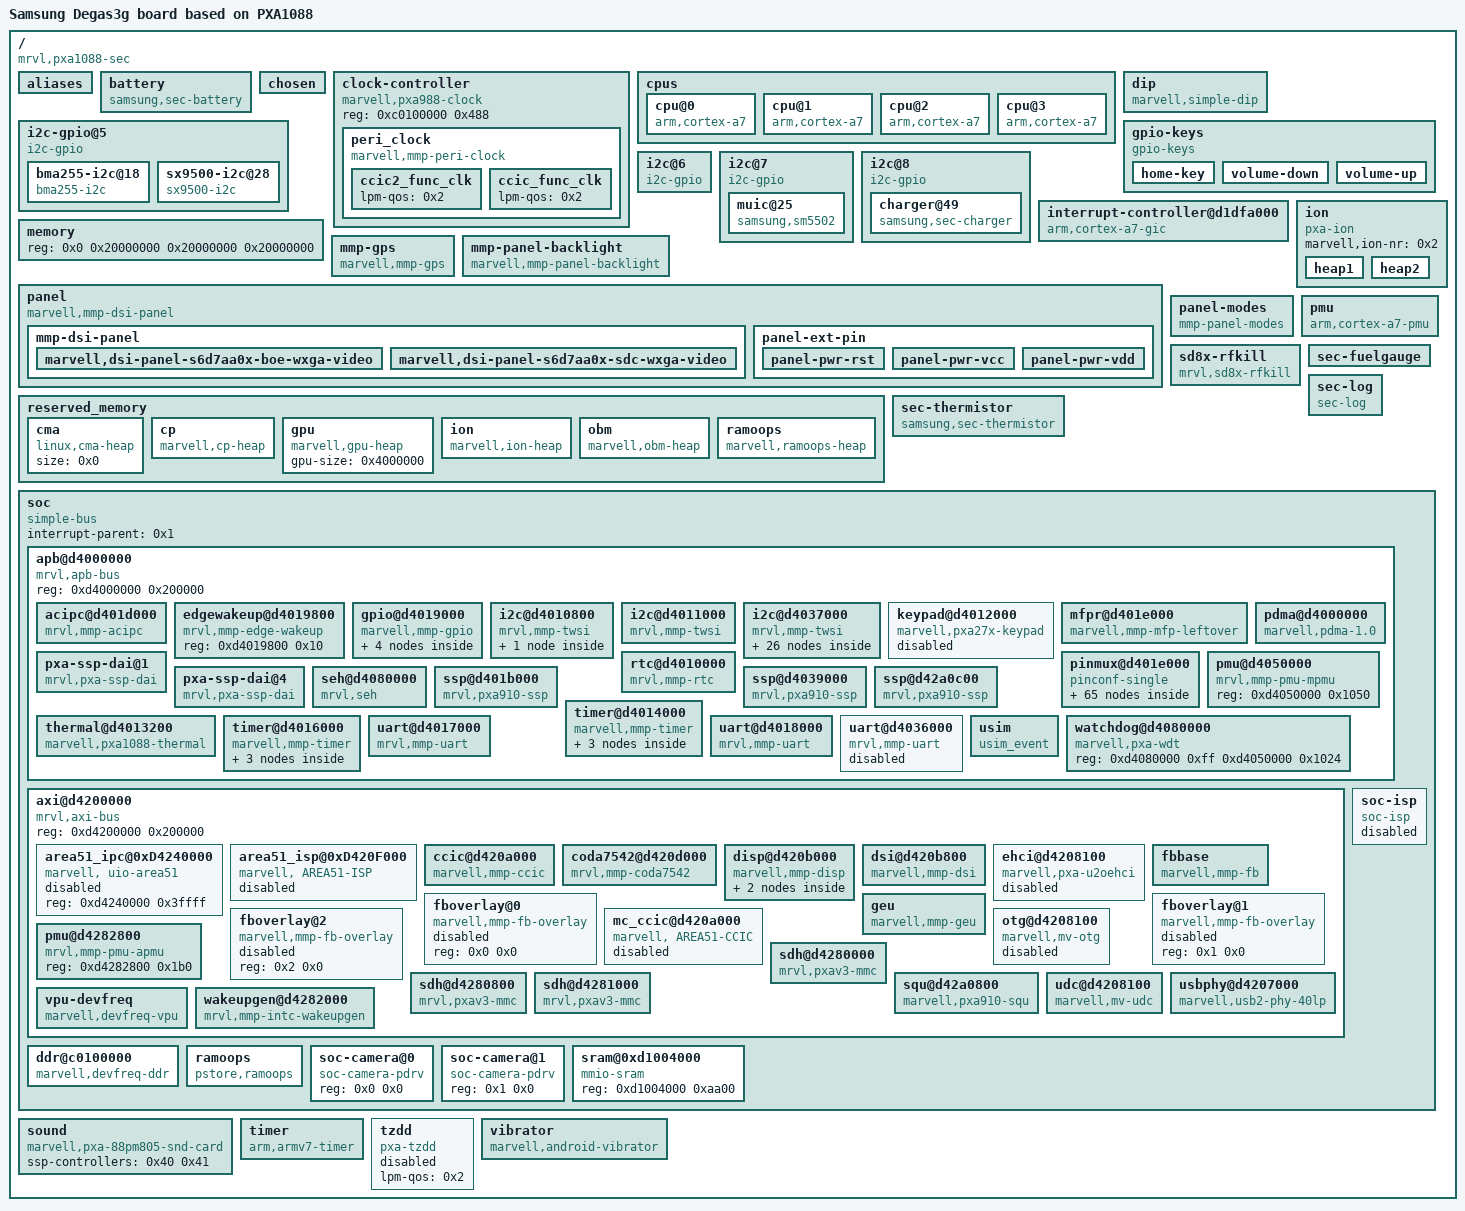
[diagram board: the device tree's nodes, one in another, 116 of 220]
/dts-v1/;

/ {
	#address-cells = <0x1>;
	#size-cells = <0x1>;
	compatible = "mrvl,pxa1088-sec", "mrvl,pxa1088";
	interrupt-parent = <0x1>;
	model = "Samsung Degas3g board based on PXA1088";
	pxa,rev-id = <0xf45 0x1>;

	aliases {
		area51-ccic0 = "/soc/axi@d4200000/mc_ccic@d420a000";
		i2c0 = "/soc/apb@d4000000/i2c@d4011000";
		i2c1 = "/soc/apb@d4000000/i2c@d4010800";
		i2c2 = "/soc/apb@d4000000/i2c@d4037000";
		i2c5 = "/i2c-gpio@5";
		i2c6 = "/i2c@6";
		i2c7 = "/i2c@7";
		i2c8 = "/i2c@8";
		mmp-camera0 = "/soc/axi@d4200000/ccic@d420a000";
		serial0 = "/soc/apb@d4000000/uart@d4036000";
		serial1 = "/soc/apb@d4000000/uart@d4017000";
		serial2 = "/soc/apb@d4000000/uart@d4018000";
	};

	battery {
		adc_check_count = <0x5>;
		battery_check_type = <0x4>;
		cable_check_type = <0x5>;
		cable_source_type = <0x1>;
		charger_name = "sec-charger";
		charging_reset_time = <0x0>;
		charging_total_time = <0x5460>;
		check_adc_max = <0x5a0>;
		check_adc_min = <0x0>;
		check_count = <0x0>;
		chg_gpio_full_check = <0x0>;
		chg_polarity_full_check = <0x1>;
		chip_vendor = "LSI";
		compatible = "samsung,sec-battery";
		event_waiting_time = <0x258>;
		fast_charging_current = <0x3e8 0x0 0x0 0x4b0 0x1cc 0x3e8 0x3e8 0x1cc 0x1f4 0x0 0x384 0x3e8 0x0 0x0 0x0 0x190 0x2bc 0x3e8 0x12c 0x3e8 0x3e8>;
		fuelgauge_name = "sec-fuelgauge";
		full_check_count = <0x1>;
		full_check_current_1st = <0xfa 0x0 0x0 0xfa 0xfa 0xfa 0xfa 0xfa 0xfa 0x0 0xfa 0xfa 0x0 0x0 0x0 0xfa 0xfa 0xfa 0xfa 0xfa 0xfa>;
		full_check_current_2nd = <0x960 0x0 0x0 0x960 0x960 0x960 0x960 0x960 0x960 0x0 0x960 0x960 0x0 0x0 0x0 0x960 0x960 0x960 0x960 0x960 0x960>;
		full_check_type = <0x7>;
		full_check_type_2nd = <0x3>;
		full_condition_soc = <0x64>;
		full_condition_type = <0xd>;
		full_condition_vcell = <0x10cc>;
		input_current_limit = <0x3b6 0x0 0x0 0x3e8 0x1cc 0x3b6 0x3b6 0x1cc 0x1f4 0x0 0x2f8 0x3b6 0x0 0x0 0x0 0x190 0x2bc 0x3b6 0x12c 0x3b6 0x3b6>;
		monitor_initial_count = <0x0>;
		ovp_uvlo_check_type = <0x4>;
		polling_time = <0xa 0x1e 0x1e 0x1e 0xe10>;
		polling_type = <0x1>;
		recharge_check_count = <0x2>;
		recharge_condition_soc = <0x62>;
		recharge_condition_type = <0x4>;
		recharge_condition_vcell = <0x10cc>;
		recharging_total_time = <0x1518>;
		status = "okay";
		technology = <0x2>;
		temp_check_count = <0x1>;
		temp_check_type = <0x2>;
		temp_high_recovery_event = <0x1cc>;
		temp_high_recovery_lpm = <0x1cc>;
		temp_high_recovery_normal = <0x1cc>;
		temp_high_threshold_event = <0x258>;
		temp_high_threshold_lpm = <0x21c>;
		temp_high_threshold_normal = <0x21c>;
		temp_low_recovery_event = <0x0>;
		temp_low_recovery_lpm = <0x1e>;
		temp_low_recovery_normal = <0x1e>;
		temp_low_threshold_event = <0xffffffe2>;
		temp_low_threshold_lpm = <0xffffffce>;
		temp_low_threshold_normal = <0xffffffce>;
		temp_table_adc = <0x114 0x146 0x17f 0x1c7 0x212 0x275 0x2e4 0x313 0x362 0x3f5 0x49d 0x551 0x61c 0x700 0x7e8 0x8d7 0x9bd 0xaa8 0xb84 0xbc3 0xc3f 0xc88 0xcf1 0xd89 0xe04 0xe72 0xec3>;
		temp_table_data = <0x384 0x352 0x320 0x2ee 0x2bc 0x28a 0x258 0x244 0x226 0x1f4 0x1c2 0x190 0x15e 0x12c 0xfa 0xc8 0x96 0x64 0x32 0x1e 0x0 0xffffffec 0xffffffce 0xffffff9c 0xffffff6a 0xffffff38 0xffffff06>;
		thermal_source = <0x0>;
		vendor = "SDI SDI";
	};

	chosen {
	};

	clock-controller {
		compatible = "marvell,pxa988-clock";
		reg = <0xc0100000 0x488>;
		reg-names = "dmcu";

		peri_clock {
			compatible = "marvell,mmp-peri-clock";

			ccic2_func_clk {
				lpm-qos = <0x2>;
			};

			ccic_func_clk {
				lpm-qos = <0x2>;
			};
		};
	};

	cpus {

		cpu@0 {
			compatible = "arm,cortex-a7";
		};

		cpu@1 {
			compatible = "arm,cortex-a7";
		};

		cpu@2 {
			compatible = "arm,cortex-a7";
		};

		cpu@3 {
			compatible = "arm,cortex-a7";
		};
	};

	dip {
		compatible = "marvell,simple-dip";
	};

	gpio-keys {
		compatible = "gpio-keys";
		edge-wakeup-gpio = <0xd>;
		pinctrl-0 = <0x3e>;
		pinctrl-1 = <0x3f>;
		pinctrl-names = "default", "sleep";
		status = "okay";

		home-key {
			debounce-interval = <0x1e>;
			gpio-key,wakeup;
			gpios = <0xc 0xd 0x1>;
			label = "Home_key";
			linux,code = <0x66>;
		};

		volume-down {
			debounce-interval = <0x1e>;
			gpios = <0xc 0x2 0x1>;
			label = "Volume_down";
			linux,code = <0x72>;
		};

		volume-up {
			debounce-interval = <0x1e>;
			gpios = <0xc 0x1 0x1>;
			label = "Volume_up";
			linux,code = <0x73>;
		};
	};

	i2c-gpio@5 {
		#address-cells = <0x1>;
		#size-cells = <0x0>;
		compatible = "i2c-gpio";
		gpios = <0xc 0x24 0x0 0xc 0x23 0x0>;
		pinctrl-0 = <0x47>;
		pinctrl-names = "default";
		status = "okay";

		bma255-i2c@18 {
			acc_chip_pos = <0x7>;
			acc_int = <0xc 0xa 0x0>;
			compatible = "bma255-i2c";
			interrupt-parent = <0xc>;
			interrupts = <0xa 0x1>;
			pinctrl-0 = <0x48>;
			pinctrl-1 = <0x49>;
			pinctrl-names = "default", "sleep";
			reg = <0x18>;
		};

		sx9500-i2c@28 {
			compatible = "sx9500-i2c";
			grip_Nirq = <0xc 0x21 0x0>;
			interrupt-parent = <0xc>;
			interrupts = <0x22 0x2>;
			pinctrl-0 = <0x4a>;
			pinctrl-names = "default", "sleep";
			reg = <0x28>;
		};
	};

	i2c@6 {
		compatible = "i2c-gpio";
		gpios = <0xc 0x1e 0x0 0xc 0x1d 0x0>;
		i2c-gpio,delay-us = <0x3>;
		i2c-gpio,timeout-ms = <0x64>;
		pinctrl-0 = <0x4b>;
		pinctrl-names = "default";
		status = "okay";
	};

	i2c@7 {
		#address-cells = <0x1>;
		#size-cells = <0x0>;
		compatible = "i2c-gpio";
		gpios = <0xc 0x32 0x0 0xc 0x31 0x0>;
		i2c-gpio,delay-us = <0x3>;
		i2c-gpio,timeout-ms = <0x64>;
		pinctrl-0 = <0x42>;
		pinctrl-names = "default";
		reg = <0x2 0x0>;
		status = "okay";

		muic@25 {
			compatible = "samsung,sm5502";
			connector-gpio = <0xc 0x5d 0x0>;
			interrupt-parent = <0xc>;
			interrupts = <0x5d 0x1>;
			lpm-qos = <0x2>;
			pinctrl-0 = <0x43>;
			pinctrl-names = "default", "sleep";
			reg = <0x25>;
		};
	};

	i2c@8 {
		#address-cells = <0x1>;
		#size-cells = <0x0>;
		compatible = "i2c-gpio";
		gpios = <0xc 0x11 0x0 0xc 0x10 0x0>;
		i2c-gpio,delay-us = <0x3>;
		i2c-gpio,timeout-ms = <0x64>;
		pinctrl-0 = <0x44>;
		pinctrl-names = "default";
		reg = <0x3 0x0>;
		status = "okay";

		charger@49 {
			chg-float-voltage = <0x10fe>;
			chg-irq-attr = <0x3>;
			chgen-gpio = <0xc 0x14 0x0>;
			chgirq-gpio = <0xc 0x8 0x0>;
			compatible = "samsung,sec-charger";
			interrupt-parent = <0xc>;
			pinctrl-0 = <0x45 0x46>;
			pinctrl-names = "default";
			reg = <0x49>;
		};
	};

	interrupt-controller@d1dfa000 {
		#interrupt-cells = <0x3>;
		compatible = "arm,cortex-a7-gic";
		interrupt-controller;
		linux,phandle = <0x1>;
		phandle = <0x1>;
		reg = <0xd1df9000 0x1000 0xd1dfa000 0x2000>;
	};

	ion {
		compatible = "pxa-ion";
		marvell,ion-nr = <0x2>;
		status = "okay";

		heap1 {
			marvell,ion-id = <0x2>;
			marvell,ion-name = "carveout_heap";
			marvell,ion-type = <0x2>;
		};

		heap2 {
			marvell,ion-id = <0x0>;
			marvell,ion-name = "system_heap";
			marvell,ion-type = <0x0>;
		};
	};

	memory {
		device_type = "memory";
		reg = <0x0 0x20000000 0x20000000 0x20000000>;
	};

	mmp-gps {
		compatible = "marvell,mmp-gps";
		marvell,gps-eclk-ctrl;
		on-off-gpio = <0xc 0x4 0x0>;
		pinctrl-0 = <0x57 0x58 0x59>;
		pinctrl-1 = <0x5a>;
		pinctrl-names = "default", "idle";
		reset-n-gpio = <0xc 0x5 0x0>;
		vgps-supply = <0x56>;
	};

	mmp-panel-backlight {
		compatible = "marvell,mmp-panel-backlight";
		linux,phandle = <0x52>;
		marvell,panel-backlight-brt-range = <0x0 0x0 0xa 0x2 0xa 0x2 0x8f 0x49 0xff 0xaa>;
		marvell,panel-backlight-name = "panel";
		phandle = <0x52>;
	};

	panel {
		compatible = "marvell,mmp-dsi-panel";
		interrupt-parent = <0xc>;
		interrupts = <0x6 0x1>;
		marvell,dsi-panel = <0x51>;
		marvell,panel-backlight = <0x52>;
		marvell,panel-esd-en;
		marvell,panel-esd-gpio = <0xc 0x13 0x0>;
		marvell,panel-esd-type = <0x1>;
		marvell,path-name = "mmp_pnpath";
		pinctrl-0 = <0x4d 0x4e 0x4f>;
		pinctrl-1 = <0x4e>;
		pinctrl-2 = <0x50>;
		pinctrl-names = "default", "enable", "disable";

		mmp-dsi-panel {
			linux,phandle = <0x51>;
			phandle = <0x51>;

			marvell,dsi-panel-s6d7aa0x-boe-wxga-video {
				marvell,dsi-burst-mode = <0x2>;
				marvell,dsi-h-back-porch = <0x30>;
				marvell,dsi-h-front-porch = <0x10>;
				marvell,dsi-h-sync-width = <0x10>;
				marvell,dsi-hbp-en;
				marvell,dsi-hfp-en;
				marvell,dsi-hsync-invert = <0x0>;
				marvell,dsi-lanes = <0x4>;
				marvell,dsi-master-mode;
				marvell,dsi-panel-backlight-get-brightness-reg = [52];
				marvell,dsi-panel-backlight-on-cmds = [15 00 00 00 02 53 24];
				marvell,dsi-panel-backlight-on-cmds-txmode = "dsi-hs-mode";
				marvell,dsi-panel-backlight-set-brightness-cmds = [15 00 00 00 02 51 57];
				marvell,dsi-panel-backlight-set-brightness-cmds-txmode = "dsi-hs-mode";
				marvell,dsi-panel-disable-cmds = <0x5002800 0x1280500 0x78000110>;
				marvell,dsi-panel-disable-cmds-txmode = "dsi-hs-mode";
				marvell,dsi-panel-enable-cmds;
				marvell,dsi-panel-enable-cmds-txmode = "dsi-hs-mode";
				marvell,dsi-panel-height = <0x96>;
				marvell,dsi-panel-id = <0x5eb810>;
				marvell,dsi-panel-init-cmds = [39 00 00 00 03 f0 5a 5a 39 00 00 00 03 f1 5a 5a 39 00 00 00 03 fc a5 a5 39 00 01 00 03 d0 00 10 39 00 00 00 04 c3 cf 00 2a 39 00 00 00 04 bc 01 4e 0a 39 00 00 00 06 fd 16 10 11 23 09 39 00 00 00 07 fe 00 02 03 21 00 78 39 00 00 00 04 f2 02 08 08 15 00 78 00 02 11 00 15 00 00 00 02 35 00 15 00 00 00 02 29 00];
				marvell,dsi-panel-init-cmds-txmode = "dsi-lp-mode";
				marvell,dsi-panel-manu = "BOE";
				marvell,dsi-panel-mdnie-browser-mode-cmds = [39 00 00 00 11 e8 00 00 00 00 00 00 00 00 00 00 00 00 00 00 00 00 39 00 00 00 19 e9 00 ff ff 00 ff 00 ff 00 00 ff ff 00 ff 00 ff 00 00 ff ff 00 ff 00 ff 00 39 00 00 00 19 ea 00 20 00 20 00 20 00 20 00 20 00 20 00 20 00 20 00 20 00 20 00 20 00 20 39 00 00 00 19 eb 00 20 00 20 00 20 00 20 00 20 00 20 00 20 00 20 00 20 00 20 00 20 00 ff 39 00 00 00 13 ec 04 7e 1f 96 1f ec 1f ca 04 4a 1f ec 1f ca 1f 97 04 9f 39 00 00 00 08 e7 08 03 03 20 05 00 02];
				marvell,dsi-panel-mdnie-browser-mode-cmds-txmode = "dsi-hs-mode";
				marvell,dsi-panel-mdnie-camera-mode-cmds = [39 00 00 00 11 e8 00 00 00 00 00 00 00 00 00 00 00 00 00 00 00 00 39 00 00 00 19 e9 00 ff ff 00 ff 00 ff 00 00 ff ff 00 ff 00 ff 00 00 ff ff 00 ff 00 ff 00 39 00 00 00 19 ea 00 20 00 20 00 20 00 20 00 20 00 20 00 20 00 20 00 20 00 20 00 20 00 20 39 00 00 00 19 eb 00 20 00 20 00 20 00 20 00 20 00 20 00 20 00 20 00 20 00 20 00 20 00 ff 39 00 00 00 13 ec 04 7e 1f 96 1f ec 1f ca 04 4a 1f ec 1f ca 1f 97 04 9f 39 00 00 00 08 e7 08 03 03 20 05 00 02];
				marvell,dsi-panel-mdnie-camera-mode-cmds-txmode = "dsi-hs-mode";
				marvell,dsi-panel-mdnie-cmd-len = <0x71>;
				marvell,dsi-panel-mdnie-cmd-reg = [e6];
				marvell,dsi-panel-mdnie-color-adjustment-mode-cmds = [39 00 00 00 11 e8 00 00 00 00 00 00 00 00 00 00 00 00 00 00 00 00 39 00 00 00 19 e9 00 ff ff 00 ff 00 ff 00 00 ff ff 00 ff 00 ff 00 00 ff ff 00 ff 00 ff 00 39 00 00 00 19 ea 00 20 00 20 00 20 00 20 00 20 00 20 00 20 00 20 00 20 00 20 00 20 00 20 39 00 00 00 19 eb 00 20 00 20 00 20 00 20 00 20 00 20 00 20 00 20 00 20 00 20 00 20 00 ff 39 00 00 00 13 ec 04 00 00 00 00 00 00 00 04 00 00 00 00 00 00 00 04 00 39 00 00 00 08 e7 08 30 03 20 05 00 00];
				marvell,dsi-panel-mdnie-color-adjustment-mode-cmds-txmode = "dsi-hs-mode";
				marvell,dsi-panel-mdnie-ebook-mode-cmds = [39 00 00 00 11 e8 00 00 00 00 00 00 00 00 00 00 00 00 00 00 00 00 39 00 00 00 19 e9 00 ff ff 00 ff 00 ff 00 00 ff ff 00 ff 00 ff 00 00 ff f5 00 ff 00 e4 00 39 00 00 00 19 ea 00 20 00 20 00 20 00 20 00 20 00 20 00 20 00 20 00 20 00 20 00 20 00 20 39 00 00 00 19 eb 00 20 00 20 00 20 00 20 00 20 00 20 00 20 00 20 00 20 00 20 00 20 00 ff 39 00 00 00 13 ec 04 00 00 00 00 00 00 00 04 00 00 00 00 00 00 00 04 00 39 00 00 00 08 e7 08 30 03 20 05 00 00];
				marvell,dsi-panel-mdnie-ebook-mode-cmds-txmode = "dsi-hs-mode";
				marvell,dsi-panel-mdnie-email-mode-cmds = [39 00 00 00 11 e8 00 00 00 00 00 00 00 00 00 00 00 00 00 00 00 00 39 00 00 00 19 e9 00 ff ff 00 ff 00 ff 00 00 ff ff 00 ff 00 ff 00 00 ff fd 00 ff 00 f4 00 39 00 00 00 19 ea 00 20 00 20 00 20 00 20 00 20 00 20 00 20 00 20 00 20 00 20 00 20 00 20 39 00 00 00 19 eb 00 20 00 20 00 20 00 20 00 20 00 20 00 20 00 20 00 20 00 20 00 20 00 ff 39 00 00 00 13 ec 04 00 00 00 00 00 00 00 04 00 00 00 00 00 00 00 04 00 39 00 00 00 08 e7 08 30 03 20 05 00 00];
				marvell,dsi-panel-mdnie-email-mode-cmds-txmode = "dsi-hs-mode";
				marvell,dsi-panel-mdnie-gallery-mode-cmds = [39 00 00 00 11 e8 00 00 00 00 00 00 00 00 00 00 00 00 00 00 00 00 39 00 00 00 19 e9 00 ff ff 00 ff 00 ff 00 00 ff ff 00 ff 00 ff 00 00 ff ff 00 ff 00 ff 00 39 00 00 00 19 ea 00 20 00 20 00 20 00 20 00 20 00 20 00 20 00 20 00 20 00 20 00 20 00 20 39 00 00 00 19 eb 00 20 00 20 00 20 00 20 00 20 00 20 00 20 00 20 00 20 00 20 00 20 00 ff 39 00 00 00 13 ec 04 7e 1f 96 1f ec 1f ca 04 4a 1f ec 1f ca 1f 97 04 9f 39 00 00 00 08 e7 08 03 03 20 05 00 06];
				marvell,dsi-panel-mdnie-gallery-mode-cmds-txmode = "dsi-hs-mode";
				marvell,dsi-panel-mdnie-negative-mode-cmds = [39 00 00 00 11 e8 00 00 00 00 00 00 00 00 00 00 00 00 00 00 00 00 39 00 00 00 19 e9 ff 00 00 ff 00 ff 00 ff ff 00 00 ff 00 ff 00 ff ff 00 00 ff 00 ff 00 ff 39 00 00 00 19 ea 00 20 00 20 00 20 00 20 00 20 00 20 00 20 00 20 00 20 00 20 00 20 00 20 39 00 00 00 19 eb 00 20 00 20 00 20 00 20 00 20 00 20 00 20 00 20 00 20 00 20 00 20 00 ff 39 00 00 00 13 ec 04 00 00 00 00 00 00 00 04 00 00 00 00 00 00 00 04 00 39 00 00 00 08 e7 08 30 03 20 05 00 00];
				marvell,dsi-panel-mdnie-negative-mode-cmds-txmode = "dsi-hs-mode";
				marvell,dsi-panel-mdnie-support;
				marvell,dsi-panel-mdnie-ui-mode-cmds = [39 00 00 00 11 e8 00 00 00 00 00 00 00 00 00 00 00 00 00 00 00 00 39 00 00 00 19 e9 00 ff ff 00 ff 00 ff 00 00 ff ff 00 ff 00 ff 00 00 ff ff 00 ff 00 ff 00 39 00 00 00 19 ea 00 20 00 20 00 20 00 20 00 20 00 20 00 20 00 20 00 20 00 20 00 20 00 20 39 00 00 00 19 eb 00 20 00 20 00 20 00 20 00 20 00 20 00 20 00 20 00 20 00 20 00 20 00 ff 39 00 00 00 13 ec 04 7e 1f 96 1f ec 1f ca 04 4a 1f ec 1f ca 1f 97 04 9f 39 00 00 00 08 e7 08 03 03 20 05 00 02];
				marvell,dsi-panel-mdnie-ui-mode-cmds-txmode = "dsi-hs-mode";
				marvell,dsi-panel-mdnie-video-mode-cmds = [39 00 00 00 11 e8 00 00 00 00 00 00 00 00 00 00 00 00 00 00 00 00 39 00 00 00 19 e9 00 ff ff 00 ff 00 ff 00 00 ff ff 00 ff 00 ff 00 00 ff ff 00 ff 00 ff 00 39 00 00 00 19 ea 00 20 00 20 00 20 00 20 00 20 00 20 00 20 00 20 00 20 00 20 00 20 00 20 39 00 00 00 19 eb 00 20 00 20 00 20 00 20 00 20 00 20 00 20 00 20 00 20 00 20 00 20 00 ff 39 00 00 00 13 ec 04 7e 1f 96 1f ec 1f ca 04 4a 1f ec 1f ca 1f 97 04 9f 39 00 00 00 08 e7 08 03 03 20 05 00 06];
				marvell,dsi-panel-mdnie-video-mode-cmds-txmode = "dsi-hs-mode";
				marvell,dsi-panel-mdnie-vt-mode-cmds = [39 00 00 00 11 e8 00 00 00 00 00 00 00 00 00 00 00 00 00 00 00 00 39 00 00 00 19 e9 00 ff ff 00 ff 00 ff 00 00 ff ff 00 ff 00 ff 00 00 ff ff 00 ff 00 ff 00 39 00 00 00 19 ea 00 20 00 20 00 20 00 20 00 20 00 20 00 20 00 20 00 20 00 20 00 20 00 20 39 00 00 00 19 eb 00 20 00 20 00 20 00 20 00 20 00 20 00 20 00 20 00 20 00 20 00 20 00 ff 39 00 00 00 13 ec 04 7e 1f 96 1f ec 1f ca 04 4a 1f ec 1f ca 1f 97 04 9f 39 00 00 00 08 e7 08 03 03 20 05 00 06];
				marvell,dsi-panel-mdnie-vt-mode-cmds-txmode = "dsi-hs-mode";
				marvell,dsi-panel-model = "BP070WX1-300";
				marvell,dsi-panel-name = "s6d7aa0x-boe";
				marvell,dsi-panel-read-id-regs = [da db dc];
				marvell,dsi-panel-read-status-ok = [9a];
				marvell,dsi-panel-read-status-reg = [0a];
				marvell,dsi-panel-type = "video_mode";
				marvell,dsi-panel-width = <0x5e>;
				marvell,dsi-panel-xres = <0x320>;
				marvell,dsi-panel-yres = <0x500>;
				marvell,dsi-v-back-porch = <0x6>;
				marvell,dsi-v-front-porch = <0x8>;
				marvell,dsi-v-sync-width = <0x2>;
				marvell,dsi-vsync-invert = <0x0>;
				status = "okay";
			};

			marvell,dsi-panel-s6d7aa0x-sdc-wxga-video {
				marvell,dsi-burst-mode = <0x2>;
				marvell,dsi-h-back-porch = <0x30>;
				marvell,dsi-h-front-porch = <0x10>;
				marvell,dsi-h-sync-width = <0x10>;
				marvell,dsi-hbp-en;
				marvell,dsi-hfp-en;
				marvell,dsi-hsync-invert = <0x0>;
				marvell,dsi-lanes = <0x4>;
				marvell,dsi-master-mode;
				marvell,dsi-panel-backlight-get-brightness-reg = [52];
				marvell,dsi-panel-backlight-on-cmds = [15 00 00 00 02 53 24];
				marvell,dsi-panel-backlight-on-cmds-txmode = "dsi-hs-mode";
				marvell,dsi-panel-backlight-set-brightness-cmds = [15 00 00 00 02 51 57];
				marvell,dsi-panel-backlight-set-brightness-cmds-txmode = "dsi-hs-mode";
				marvell,dsi-panel-disable-cmds = <0x5002800 0x1280500 0x78000110>;
				marvell,dsi-panel-disable-cmds-txmode = "dsi-hs-mode";
				marvell,dsi-panel-enable-cmds;
				marvell,dsi-panel-enable-cmds-txmode = "dsi-hs-mode";
				marvell,dsi-panel-height = <0x96>;
				marvell,dsi-panel-id = <0x5e8810>;
				marvell,dsi-panel-init-cmds = [39 00 00 00 03 f0 5a 5a 39 00 00 00 03 f1 5a 5a 39 00 00 00 03 fc a5 a5 39 00 01 00 03 d0 00 10 39 00 00 00 04 c3 cf 00 2a 39 00 00 00 04 bc 01 4e 0a 39 00 00 00 06 fd 16 10 11 23 09 39 00 00 00 07 fe 00 02 03 21 00 78 39 00 00 00 04 f2 02 08 08 15 00 78 00 02 11 00 15 00 00 00 02 35 00 15 00 00 00 02 29 00];
				marvell,dsi-panel-init-cmds-txmode = "dsi-lp-mode";
				marvell,dsi-panel-manu = "SDC";
				marvell,dsi-panel-mdnie-browser-mode-cmds = [39 00 00 00 11 e8 00 00 00 00 00 00 00 00 00 00 00 00 00 00 00 00 39 00 00 00 19 e9 00 ff ff 00 ff 00 ff 00 00 ff ff 00 ff 00 ff 00 00 ff ff 00 ff 00 ff 00 39 00 00 00 19 ea 00 20 00 20 00 20 00 20 00 20 00 20 00 20 00 20 00 20 00 20 00 20 00 20 39 00 00 00 19 eb 00 20 00 20 00 20 00 20 00 20 00 20 00 20 00 20 00 20 00 20 00 20 00 ff 39 00 00 00 13 ec 04 7e 1f 96 1f ec 1f ca 04 4a 1f ec 1f ca 1f 97 04 9f 39 00 00 00 08 e7 08 03 03 20 05 00 02];
				marvell,dsi-panel-mdnie-browser-mode-cmds-txmode = "dsi-hs-mode";
				marvell,dsi-panel-mdnie-camera-mode-cmds = [39 00 00 00 11 e8 00 00 00 00 00 00 00 00 00 00 00 00 00 00 00 00 39 00 00 00 19 e9 00 ff ff 00 ff 00 ff 00 00 ff ff 00 ff 00 ff 00 00 ff ff 00 ff 00 ff 00 39 00 00 00 19 ea 00 20 00 20 00 20 00 20 00 20 00 20 00 20 00 20 00 20 00 20 00 20 00 20 39 00 00 00 19 eb 00 20 00 20 00 20 00 20 00 20 00 20 00 20 00 20 00 20 00 20 00 20 00 ff 39 00 00 00 13 ec 04 7e 1f 96 1f ec 1f ca 04 4a 1f ec 1f ca 1f 97 04 9f 39 00 00 00 08 e7 08 03 03 20 05 00 02];
				marvell,dsi-panel-mdnie-camera-mode-cmds-txmode = "dsi-hs-mode";
				marvell,dsi-panel-mdnie-cmd-len = <0x71>;
				marvell,dsi-panel-mdnie-cmd-reg = [e6];
				marvell,dsi-panel-mdnie-color-adjustment-mode-cmds = [39 00 00 00 11 e8 00 00 00 00 00 00 00 00 00 00 00 00 00 00 00 00 39 00 00 00 19 e9 00 ff ff 00 ff 00 ff 00 00 ff ff 00 ff 00 ff 00 00 ff ff 00 ff 00 ff 00 39 00 00 00 19 ea 00 20 00 20 00 20 00 20 00 20 00 20 00 20 00 20 00 20 00 20 00 20 00 20 39 00 00 00 19 eb 00 20 00 20 00 20 00 20 00 20 00 20 00 20 00 20 00 20 00 20 00 20 00 ff 39 00 00 00 13 ec 04 00 00 00 00 00 00 00 04 00 00 00 00 00 00 00 04 00 39 00 00 00 08 e7 08 30 03 20 05 00 00];
				marvell,dsi-panel-mdnie-color-adjustment-mode-cmds-txmode = "dsi-hs-mode";
				marvell,dsi-panel-mdnie-ebook-mode-cmds = [39 00 00 00 11 e8 00 00 00 00 00 00 00 00 00 00 00 00 00 00 00 00 39 00 00 00 19 e9 00 ff ff 00 ff 00 ff 00 00 ff ff 00 ff 00 ff 00 00 ff f5 00 ff 00 e4 00 39 00 00 00 19 ea 00 20 00 20 00 20 00 20 00 20 00 20 00 20 00 20 00 20 00 20 00 20 00 20 39 00 00 00 19 eb 00 20 00 20 00 20 00 20 00 20 00 20 00 20 00 20 00 20 00 20 00 20 00 ff 39 00 00 00 13 ec 04 00 00 00 00 00 00 00 04 00 00 00 00 00 00 00 04 00 39 00 00 00 08 e7 08 30 03 20 05 00 00];
				marvell,dsi-panel-mdnie-ebook-mode-cmds-txmode = "dsi-hs-mode";
				marvell,dsi-panel-mdnie-email-mode-cmds = [39 00 00 00 11 e8 00 00 00 00 00 00 00 00 00 00 00 00 00 00 00 00 39 00 00 00 19 e9 00 ff ff 00 ff 00 ff 00 00 ff ff 00 ff 00 ff 00 00 ff fd 00 ff 00 f4 00 39 00 00 00 19 ea 00 20 00 20 00 20 00 20 00 20 00 20 00 20 00 20 00 20 00 20 00 20 00 20 39 00 00 00 19 eb 00 20 00 20 00 20 00 20 00 20 00 20 00 20 00 20 00 20 00 20 00 20 00 ff 39 00 00 00 13 ec 04 00 00 00 00 00 00 00 04 00 00 00 00 00 00 00 04 00 39 00 00 00 08 e7 08 30 03 20 05 00 00];
				marvell,dsi-panel-mdnie-email-mode-cmds-txmode = "dsi-hs-mode";
				marvell,dsi-panel-mdnie-gallery-mode-cmds = [39 00 00 00 11 e8 00 00 00 00 00 00 00 00 00 00 00 00 00 00 00 00 39 00 00 00 19 e9 00 ff ff 00 ff 00 ff 00 00 ff ff 00 ff 00 ff 00 00 ff ff 00 ff 00 ff 00 39 00 00 00 19 ea 00 20 00 20 00 20 00 20 00 20 00 20 00 20 00 20 00 20 00 20 00 20 00 20 39 00 00 00 19 eb 00 20 00 20 00 20 00 20 00 20 00 20 00 20 00 20 00 20 00 20 00 20 00 ff 39 00 00 00 13 ec 04 7e 1f 96 1f ec 1f ca 04 4a 1f ec 1f ca 1f 97 04 9f 39 00 00 00 08 e7 08 03 03 20 05 00 06];
				marvell,dsi-panel-mdnie-gallery-mode-cmds-txmode = "dsi-hs-mode";
				marvell,dsi-panel-mdnie-negative-mode-cmds = [39 00 00 00 11 e8 00 00 00 00 00 00 00 00 00 00 00 00 00 00 00 00 39 00 00 00 19 e9 ff 00 00 ff 00 ff 00 ff ff 00 00 ff 00 ff 00 ff ff 00 00 ff 00 ff 00 ff 39 00 00 00 19 ea 00 20 00 20 00 20 00 20 00 20 00 20 00 20 00 20 00 20 00 20 00 20 00 20 39 00 00 00 19 eb 00 20 00 20 00 20 00 20 00 20 00 20 00 20 00 20 00 20 00 20 00 20 00 ff 39 00 00 00 13 ec 04 00 00 00 00 00 00 00 04 00 00 00 00 00 00 00 04 00 39 00 00 00 08 e7 08 30 03 20 05 00 00];
				marvell,dsi-panel-mdnie-negative-mode-cmds-txmode = "dsi-hs-mode";
				marvell,dsi-panel-mdnie-support;
				marvell,dsi-panel-mdnie-ui-mode-cmds = [39 00 00 00 11 e8 00 00 00 00 00 00 00 00 00 00 00 00 00 00 00 00 39 00 00 00 19 e9 00 ff ff 00 ff 00 ff 00 00 ff ff 00 ff 00 ff 00 00 ff ff 00 ff 00 ff 00 39 00 00 00 19 ea 00 20 00 20 00 20 00 20 00 20 00 20 00 20 00 20 00 20 00 20 00 20 00 20 39 00 00 00 19 eb 00 20 00 20 00 20 00 20 00 20 00 20 00 20 00 20 00 20 00 20 00 20 00 ff 39 00 00 00 13 ec 04 7e 1f 96 1f ec 1f ca 04 4a 1f ec 1f ca 1f 97 04 9f 39 00 00 00 08 e7 08 03 03 20 05 00 02];
				marvell,dsi-panel-mdnie-ui-mode-cmds-txmode = "dsi-hs-mode";
				marvell,dsi-panel-mdnie-video-mode-cmds = [39 00 00 00 11 e8 00 00 00 00 00 00 00 00 00 00 00 00 00 00 00 00 39 00 00 00 19 e9 00 ff ff 00 ff 00 ff 00 00 ff ff 00 ff 00 ff 00 00 ff ff 00 ff 00 ff 00 39 00 00 00 19 ea 00 20 00 20 00 20 00 20 00 20 00 20 00 20 00 20 00 20 00 20 00 20 00 20 39 00 00 00 19 eb 00 20 00 20 00 20 00 20 00 20 00 20 00 20 00 20 00 20 00 20 00 20 00 ff 39 00 00 00 13 ec 04 7e 1f 96 1f ec 1f ca 04 4a 1f ec 1f ca 1f 97 04 9f 39 00 00 00 08 e7 08 03 03 20 05 00 06];
				marvell,dsi-panel-mdnie-video-mode-cmds-txmode = "dsi-hs-mode";
				marvell,dsi-panel-mdnie-vt-mode-cmds = [39 00 00 00 11 e8 00 00 00 00 00 00 00 00 00 00 00 00 00 00 00 00 39 00 00 00 19 e9 00 ff ff 00 ff 00 ff 00 00 ff ff 00 ff 00 ff 00 00 ff ff 00 ff 00 ff 00 39 00 00 00 19 ea 00 20 00 20 00 20 00 20 00 20 00 20 00 20 00 20 00 20 00 20 00 20 00 20 39 00 00 00 19 eb 00 20 00 20 00 20 00 20 00 20 00 20 00 20 00 20 00 20 00 20 00 20 00 ff 39 00 00 00 13 ec 04 7e 1f 96 1f ec 1f ca 04 4a 1f ec 1f ca 1f 97 04 9f 39 00 00 00 08 e7 08 03 03 20 05 00 06];
				marvell,dsi-panel-mdnie-vt-mode-cmds-txmode = "dsi-hs-mode";
				marvell,dsi-panel-model = "LTL070AL03";
				marvell,dsi-panel-name = "s6d7aa0x-sdc";
				marvell,dsi-panel-read-id-regs = [da db dc];
				marvell,dsi-panel-read-status-ok = [9a];
				marvell,dsi-panel-read-status-reg = [0a];
				marvell,dsi-panel-type = "video_mode";
				marvell,dsi-panel-width = <0x5e>;
				marvell,dsi-panel-xres = <0x320>;
				marvell,dsi-panel-yres = <0x500>;
				marvell,dsi-v-back-porch = <0x6>;
				marvell,dsi-v-front-porch = <0x8>;
				marvell,dsi-v-sync-width = <0x2>;
				marvell,dsi-vsync-invert = <0x0>;
				status = "okay";
			};
		};

		panel-ext-pin {
			panel-ext-pin-off = <0x55 0x0 0xa 0x53 0x0 0xa 0x54 0x0 0xa>;
			panel-ext-pin-on = <0x53 0x1 0x0 0x54 0x1 0x0 0x55 0x1 0x14 0x55 0x0 0x7d0 0x55 0x1 0x1388>;

			panel-pwr-rst {
				linux,phandle = <0x55>;
				panel-ext-pin-gpio = <0xc 0x12 0x0>;
				panel-ext-pin-name = "rst";
				panel-ext-pin-type = <0x0>;
				phandle = <0x55>;
			};

			panel-pwr-vcc {
				linux,phandle = <0x53>;
				panel-ext-pin-gpio = <0xc 0x6 0x0>;
				panel-ext-pin-name = "vcc";
				panel-ext-pin-type = <0x0>;
				phandle = <0x53>;
			};

			panel-pwr-vdd {
				linux,phandle = <0x54>;
				panel-ext-pin-gpio = <0xc 0x7 0x0>;
				panel-ext-pin-name = "vdd";
				panel-ext-pin-type = <0x0>;
				phandle = <0x54>;
			};
		};
	};

	panel-modes {
		compatible = "mmp-panel-modes";
		xres = <0x320>;
		yres = <0x500>;
	};

	pmu {
		compatible = "arm,cortex-a7-pmu";
		interrupts = <0x0 0x3a 0x4 0x0 0x3d 0x4 0x0 0x42 0x4 0x0 0x44 0x4>;
	};

	reserved_memory {

		cma {
			compatible = "linux,cma-heap";
			size = <0x0>;
			status = "okay";
		};

		cp {
			compatible = "marvell,cp-heap";
			cp-base = <0x6000000>;
			cp-size = <0x2000000>;
			status = "okay";
		};

		gpu {
			compatible = "marvell,gpu-heap";
			gpu-size = <0x4000000>;
			status = "okay";
		};

		ion {
			compatible = "marvell,ion-heap";
			ion-base = <0x9000000>;
			ion-size = <0x7000000>;
			status = "okay";
		};

		obm {
			compatible = "marvell,obm-heap";
			obm-base-default = <0x0>;
			obm-base-with-crash-dump = <0x6000000>;
			obm-base-with-tz = <0x1000000>;
			obm-size = <0x100000>;
			status = "okay";
		};

		ramoops {
			compatible = "marvell,ramoops-heap";
			ramoops-base = <0x8100000>;
			ramoops-size = <0x40000>;
			status = "okay";
		};
	};

	sd8x-rfkill {
		compatible = "mrvl,sd8x-rfkill";
		edge-wakeup-gpio = <0xc 0x27 0x0>;
		hostwu-gpio = <0xc 0x53 0x0>;
		pd-gpio = <0xc 0x33 0x0>;
		sd-host = <0x3c>;
		status = "okay";
		v_wib_3v3-supply = <0x3d>;
	};

	sec-fuelgauge {
		capacity-max = <0x3e8>;
		capacity-max-margin = <0x1e>;
		capacity-min = <0x0>;
		fg-irq-attr = <0x2>;
		fuel-alert-soc = <0x1>;
		temp_adc_channel = <0x2>;
	};

	sec-log {
		compatible = "sec-log";
		status = "okay";
	};

	sec-thermistor {
		adc-channel = <0x1>;
		adc_array = <0x45 0x4b 0x51 0x57 0x5d 0x63 0x6a 0x71 0x78 0x7f 0x87 0x8e 0x95 0x9c 0xa3 0xaa 0xb4 0xbc 0xc4 0xcc 0xd4 0xdc 0xe4 0xec 0xf4 0xfc 0x105 0x10e 0x117 0x120 0x129 0x132 0x13b 0x144 0x14d 0x156 0x167 0x175 0x183 0x191 0x19f 0x1ad 0x1bb 0x1c9 0x1d7 0x1e5 0x1f9 0x20d 0x221 0x235 0x24e 0x262 0x27b 0x294 0x2a8 0x2bf 0x2dd 0x2fd 0x339 0x35c 0x366 0x37a 0x3a0 0x3b8 0x3dc 0x406 0x433 0x460 0x492 0x4b7 0x4ef 0x520 0x54b 0x54c 0x54d 0x54e 0x54f 0x550 0x551 0x552 0x553 0x554 0x555 0x556 0x557 0x558>;
		compatible = "samsung,sec-thermistor";
		status = "okay";
		temp_array = <0x2ee 0x2e4 0x2da 0x2d0 0x2c6 0x2bc 0x2b2 0x2a8 0x29e 0x294 0x28a 0x280 0x276 0x26c 0x262 0x258 0x24e 0x244 0x23a 0x230 0x226 0x21c 0x212 0x208 0x1fe 0x1f4 0x1ea 0x1e0 0x1d6 0x1cc 0x1c2 0x1b8 0x1ae 0x1a4 0x19a 0x190 0x186 0x17c 0x172 0x168 0x15e 0x154 0x14a 0x140 0x136 0x12c 0x122 0x118 0x10e 0x104 0xfa 0xf0 0xe6 0xdc 0xd2 0xc8 0xbe 0xb4 0xaa 0xa0 0x96 0x8c 0x82 0x78 0x6e 0x64 0x5a 0x50 0x46 0x3c 0x32 0x28 0x1e 0x14 0xa 0x0 0xfffffff6 0xffffffec 0xffffffe2 0xffffffd8 0xffffffce 0xffffffc4 0xffffffba 0xffffffb0 0xffffffa6 0xffffff9c>;
	};

	soc {
		#address-cells = <0x1>;
		#size-cells = <0x1>;
		compatible = "simple-bus";
		interrupt-parent = <0x1>;
		ranges;

		apb@d4000000 {
			#address-cells = <0x1>;
			#size-cells = <0x1>;
			compatible = "mrvl,apb-bus", "simple-bus";
			ranges;
			reg = <0xd4000000 0x200000>;

			acipc@d401d000 {
				compatible = "mrvl,mmp-acipc";
				interrupt-names = "IPC_AP_DATAACK", "IPC_AP_SET_CMD", "IPC_AP_SET_MSG";
				interrupts = <0x0 0x10 0x4 0x0 0x11 0x4 0x0 0x12 0x4>;
				reg = <0xd401d000 0x100>;
				status = "okay";
			};

			edgewakeup@d4019800 {
				compatible = "mrvl,mmp-edge-wakeup";
				reg = <0xd4019800 0x10>;
				status = "ok";
			};

			gpio@d4019000 {
				#address-cells = <0x1>;
				#gpio-cells = <0x2>;
				#interrupt-cells = <0x2>;
				#size-cells = <0x1>;
				compatible = "marvell,mmp-gpio";
				gpio-controller;
				interrupt-controller;
				interrupt-names = "gpio_mux";
				interrupts = <0x0 0x31 0x4>;
				linux,phandle = <0xc>;
				phandle = <0xc>;
				ranges;
				reg = <0xd4019000 0x800>;
				status = "okay";

				gpio@d4019000 {
					gpio-ranges = <0x24 0x0 0x37 0x20>;
					reg = <0xd4019000 0x4>;
				};

				gpio@d4019004 {
					gpio-ranges = <0x24 0x0 0x57 0x17>;
					reg = <0xd4019004 0x4>;
				};

				gpio@d4019008 {
					gpio-ranges = <0x24 0x3 0x6e 0x1d>;
					reg = <0xd4019008 0x4>;
				};

				gpio@d4019100 {
					gpio-ranges = <0x24 0x0 0x8b 0x3 0x24 0x1c 0x34 0x1>;
					reg = <0xd4019100 0x4>;
				};
			};

			i2c@d4010800 {
				#address-cells = <0x1>;
				#size-cells = <0x0>;
				compatible = "mrvl,mmp-twsi";
				i2c-gpio = <0xc 0x57 0x0 0xc 0x58 0x0>;
				interrupts = <0x0 0x21 0x4>;
				lpm-qos = <0x3>;
				marvell,i2c-always-on;
				marvell,i2c-ilcr = <0x82c469f>;
				marvell,i2c-iwcr = <0x142a>;
				mrvl,i2c-fast-mode;
				pinctrl-0 = <0x29>;
				pinctrl-1 = <0x2a>;
				pinctrl-names = "default", "gpio";
				reg = <0xd4010800 0x60>;
				status = "okay";

				tsp@20 {
					bt532,orientation = [00];
					bt532,page_size = [00 80];
					bt532,x_resolution = [03 1f];
					bt532,y_resolution = [04 ff];
					compatible = "zinitix,bt532_tsp";
					interrupt-parent = <0xc>;
					interrupts = <0x5e 0x2>;
					pinctrl-0 = <0x2b 0x2c>;
					pinctrl-names = "default";
					reg = <0x20>;
					tsp_gpio = <0xc 0x5e 0x1>;
					tsp_vdd-supply = <0x2d>;
					tsp_vdd_supply_type = <0x1>;
					tsp_vendor_1 = <0xc 0x3d 0x1>;
					tsp_vendor_2 = <0xc 0x3c 0x1>;
				};
			};

			i2c@d4011000 {
				#address-cells = <0x1>;
				#size-cells = <0x0>;
				compatible = "mrvl,mmp-twsi";
				i2c-gpio = <0xc 0x4f 0x0 0xc 0x50 0x0>;
				interrupts = <0x0 0x7 0x4>;
				lpm-qos = <0x3>;
				marvell,i2c-always-on;
				marvell,i2c-ilcr = <0x82c469f>;
				marvell,i2c-iwcr = <0x142a>;
				mrvl,i2c-fast-mode;
				pinctrl-0 = <0x27>;
				pinctrl-1 = <0x28>;
				pinctrl-names = "default", "gpio";
				reg = <0xd4011000 0x60>;
				status = "okay";
			};

			i2c@d4037000 {
				#address-cells = <0x1>;
				#size-cells = <0x0>;
				compatible = "mrvl,mmp-twsi";
				interrupts = <0x0 0x36 0x4>;
				lpm-qos = <0x3>;
				marvell,i2c-always-on;
				marvell,i2c-ilcr = <0x82c469f>;
				marvell,i2c-iwcr = <0x142a>;
				mrvl,i2c-fast-mode;
				reg = <0xd4037000 0x60 0xd403d300 0x4>;
				status = "okay";

				88pm805@38 {
					compatible = "marvell,88pm805";
					interrupt-parent = <0xc>;
					interrupts = <0x7c 0x1>;
					marvell,88pm805-irq-write-clear;
					pinctrl-0 = <0x31>;
					pinctrl-names = "default";
					reg = <0x38>;
				};

				88pm822@30 {
					#interrupt-cells = <0x1>;
					compatible = "marvell,88pm822";
					interrupt-controller;
					interrupt-parent = <0x1>;
					interrupts = <0x0 0x4 0x4>;
					marvell,88pm800-irq-write-clear;
					marvell,88pm822-gpadc-page-addr = <0x32>;
					marvell,88pm822-power-page-addr = <0x31>;
					reg = <0x30>;

					dvc {
						compatible = "marvell,88pm8xx-dvc";
						dvc-affected-buckbits = <0x15>;
						pinctrl-0 = <0x2e>;
						pinctrl-names = "default";
					};

					headset {
						compatible = "marvell,88pm80x-headset";
						headset-gdet-gpio = <0xc 0x61 0x0>;
						marvell,headset-flag = <0x0>;
						marvell,hook-press-th = <0x46>;
						marvell,mic-det-th = <0x258>;
						marvell,micbias-supply = <0x2f>;
						marvell,press-release-th = <0x3b6>;
						marvell,switch-name = "h2w";
						marvell,vol-down-press-th = <0x320>;
						marvell,vol-up-press-th = <0x12c>;
						pinctrl-0 = <0x30>;
						pinctrl-names = "default";
						sec0,adc_high = <0x0>;
						sec0,check_count = <0x2>;
						sec0,delay_ms = <0x14>;
						sec0,jack_type = <0x2>;
						sec1,adc_high = <0x3e9>;
						sec1,check_count = <0x5>;
						sec1,delay_ms = <0x14>;
						sec1,jack_type = <0x2>;
						sec2,adc_high = <0x3ea>;
						sec2,check_count = <0xa>;
						sec2,delay_ms = <0x14>;
						sec2,jack_type = <0x1>;
						sec3,adc_high = <0x6a4>;
						sec3,check_count = <0x2>;
						sec3,delay_ms = <0x14>;
						sec3,jack_type = <0x1>;
						sec4,adc_high = <0x7fffffff>;
						sec4,check_count = <0x3e8>;
						sec4,delay_ms = <0xa>;
						sec4,jack_type = <0x2>;
						sec_sendend0,adc_high = <0xaa>;
						sec_sendend0,adc_low = <0x0>;
						sec_sendend0,code = <0x4000>;
						sec_sendend1,adc_high = <0x158>;
						sec_sendend1,adc_low = <0xab>;
						sec_sendend1,code = <0x2000>;
						sec_sendend2,adc_high = <0x384>;
						sec_sendend2,adc_low = <0x159>;
						sec_sendend2,code = <0x1000>;
					};

					regulators {
						compatible = "marvell,88pm80x-regulator";

						BUCK1 {
							regulator-always-on;
							regulator-boot-on;
							regulator-compatible = "88PM800-BUCK1";
							regulator-max-microvolt = <0x1b7740>;
							regulator-min-microvolt = <0x927c0>;
						};

						BUCK2 {
							regulator-always-on;
							regulator-boot-on;
							regulator-compatible = "88PM800-BUCK2";
							regulator-max-microvolt = <0x325aa0>;
							regulator-min-microvolt = <0x927c0>;
						};

						BUCK3 {
							regulator-always-on;
							regulator-boot-on;
							regulator-compatible = "88PM800-BUCK3";
							regulator-max-microvolt = <0x325aa0>;
							regulator-min-microvolt = <0x927c0>;
						};

						BUCK4 {
							regulator-always-on;
							regulator-boot-on;
							regulator-compatible = "88PM800-BUCK4";
							regulator-max-microvolt = <0x325aa0>;
							regulator-min-microvolt = <0x927c0>;
						};

						BUCK5 {
							linux,phandle = <0x17>;
							phandle = <0x17>;
							regulator-compatible = "88PM800-BUCK5";
							regulator-max-microvolt = <0x3c45b0>;
							regulator-min-microvolt = <0x927c0>;
						};

						LDO1 {
							linux,phandle = <0x2d>;
							phandle = <0x2d>;
							regulator-boot-on;
							regulator-compatible = "88PM800-LDO1";
							regulator-max-microvolt = <0x325aa0>;
							regulator-min-microvolt = <0x19f0a0>;
						};

						LDO10 {
							linux,phandle = <0x3d>;
							phandle = <0x3d>;
							regulator-always-on;
							regulator-boot-on;
							regulator-compatible = "88PM800-LDO10";
							regulator-max-microvolt = <0x325aa0>;
							regulator-min-microvolt = <0x124f80>;
						};

						LDO11 {
							linux,phandle = <0xb>;
							phandle = <0xb>;
							regulator-compatible = "88PM800-LDO11";
							regulator-max-microvolt = <0x325aa0>;
							regulator-min-microvolt = <0x124f80>;
						};

						LDO12 {
							regulator-compatible = "88PM800-LDO12";
							regulator-max-microvolt = <0x16e360>;
							regulator-min-microvolt = <0x927c0>;
						};

						LDO13 {
							linux,phandle = <0x56>;
							phandle = <0x56>;
							regulator-always-on;
							regulator-boot-on;
							regulator-compatible = "88PM800-LDO13";
							regulator-max-microvolt = <0x325aa0>;
							regulator-min-microvolt = <0x19f0a0>;
						};

						LDO14 {
							linux,phandle = <0x2f>;
							phandle = <0x2f>;
							regulator-compatible = "88PM800-LDO14";
							regulator-max-microvolt = <0x2c4020>;
							regulator-min-microvolt = <0x1b7740>;
						};

						LDO2 {
							regulator-always-on;
							regulator-boot-on;
							regulator-compatible = "88PM800-LDO2";
							regulator-max-microvolt = <0x325aa0>;
							regulator-min-microvolt = <0x19f0a0>;
						};

						LDO3 {
							regulator-always-on;
							regulator-boot-on;
							regulator-compatible = "88PM800-LDO3";
							regulator-max-microvolt = <0x325aa0>;
							regulator-min-microvolt = <0x124f80>;
						};

						LDO4 {
							linux,phandle = <0x15>;
							phandle = <0x15>;
							regulator-compatible = "88PM800-LDO4";
							regulator-max-microvolt = <0x325aa0>;
							regulator-min-microvolt = <0x124f80>;
						};

						LDO5 {
							linux,phandle = <0xa>;
							phandle = <0xa>;
							regulator-compatible = "88PM800-LDO5";
							regulator-max-microvolt = <0x325aa0>;
							regulator-min-microvolt = <0x124f80>;
						};

						LDO6 {
							regulator-compatible = "88PM800-LDO6";
							regulator-max-microvolt = <0x325aa0>;
							regulator-min-microvolt = <0x124f80>;
						};

						LDO7 {
							regulator-always-on;
							regulator-boot-on;
							regulator-compatible = "88PM800-LDO7";
							regulator-max-microvolt = <0x325aa0>;
							regulator-min-microvolt = <0x124f80>;
						};

						LDO8 {
							regulator-always-on;
							regulator-boot-on;
							regulator-compatible = "88PM800-LDO8";
							regulator-max-microvolt = <0x325aa0>;
							regulator-min-microvolt = <0x124f80>;
						};

						LDO9 {
							linux,phandle = <0x16>;
							phandle = <0x16>;
							regulator-compatible = "88PM800-LDO9";
							regulator-max-microvolt = <0x325aa0>;
							regulator-min-microvolt = <0x124f80>;
						};

						VOUTSW {
							regulator-compatible = "88PM800-VOUTSW";
							regulator-max-microvolt = <0x1b7740>;
							regulator-min-microvolt = <0x19f0a0>;
						};
					};

					usb {
						compatible = "marvell,88pm80x-usb";
						id-gpadc = <0xff>;
						vbus-gpio = <0xff>;
					};
				};
			};

			keypad@d4012000 {
				compatible = "marvell,pxa27x-keypad";
				interrupts = <0x0 0x9 0x4>;
				lpm-qos = <0x3>;
				marvell,keypad-lpm-mod;
				reg = <0xd4012000 0x4c>;
				status = "disabled";
			};

			mfpr@d401e000 {
				compatible = "marvell,mmp-mfp-leftover";
				pinctrl-0 = <0x25 0x26>;
				pinctrl-names = "default";
				reg = <0xd401e000 0x280>;
				status = "ok";
			};

			pdma@d4000000 {
				#dma-cells = <0x2>;
				#dma-channels = <0x20>;
				#dma-channels-tz = <0x1e>;
				compatible = "marvell,pdma-1.0";
				interrupts = <0x0 0x2f 0x4>;
				linux,phandle = <0x1e>;
				lpm-qos = <0x2>;
				phandle = <0x1e>;
				reg = <0xd4000000 0x10000>;
				status = "okay";
			};

			pinmux@d401e000 {
				#address-cells = <0x1>;
				#gpio-range-cells = <0x3>;
				#size-cells = <0x1>;
				compatible = "pinconf-single";
				linux,phandle = <0x24>;
				phandle = <0x24>;
				pinctrl-single,function-mask = <0x7>;
				pinctrl-single,gpio-range = <0x32 0x37 0x37 0x0 0x32 0x6e 0x20 0x0 0x32 0x11 0x1 0x1 0x32 0x34 0x1 0x0>;
				pinctrl-single,register-width = <0x20>;
				ranges;
				reg = <0xd401e000 0x330>;

				accel_gpio_pmx {
					linux,phandle = <0x48>;
					phandle = <0x48>;
					pinctrl-single,bias-pulldown = <0xa000 0xa000 0x0 0xa000>;
					pinctrl-single,bias-pullup = <0x8000 0xc000 0x8000 0xc000>;
					pinctrl-single,drive-strength = <0x1000 0x1800>;
					pinctrl-single,input-schmitt = <0x0 0x30>;
					pinctrl-single,input-schmitt-enable = <0x40 0x0 0x40 0x40>;
					pinctrl-single,pins = <0x104 0x0>;
				};

				accel_suspend_pmx {
					linux,phandle = <0x49>;
					phandle = <0x49>;
					pinctrl-single,bias-pulldown = <0xa000 0xa000 0x0 0xa000>;
					pinctrl-single,bias-pullup = <0x8000 0xc000 0x8000 0xc000>;
					pinctrl-single,drive-strength = <0x1000 0x1800>;
					pinctrl-single,input-schmitt = <0x0 0x30>;
					pinctrl-single,input-schmitt-enable = <0x40 0x0 0x40 0x40>;
					pinctrl-single,pins = <0x104 0x0>;
				};

				cam_pmx_func1 {
					linux,phandle = <0x1d>;
					phandle = <0x1d>;
					pinctrl-single,bias-pulldown = <0xa000 0xa000 0x0 0xa000>;
					pinctrl-single,bias-pullup = <0x8000 0xc000 0x8000 0xc000>;
					pinctrl-single,drive-strength = <0x800 0x1800>;
					pinctrl-single,input-schmitt = <0x0 0x30>;
					pinctrl-single,input-schmitt-enable = <0x40 0x0 0x40 0x40>;
					pinctrl-single,lpm-output = <0x208 0x388>;
					pinctrl-single,pins = <0x1e0 0x1>;
				};

				cam_pmx_func2 {
					linux,phandle = <0x19>;
					phandle = <0x19>;
					pinctrl-single,bias-pulldown = <0x0 0xa000 0x0 0xa000>;
					pinctrl-single,bias-pullup = <0x0 0xc000 0x0 0xc000>;
					pinctrl-single,drive-strength = <0x1000 0x1800>;
					pinctrl-single,input-schmitt = <0x0 0x30>;
					pinctrl-single,input-schmitt-enable = <0x40 0x0 0x40 0x40>;
					pinctrl-single,lpm-output = <0x208 0x388>;
					pinctrl-single,pins = <0x1b8 0x1 0x1bc 0x1 0x1c0 0x1 0x1c4 0x1 0x1c8 0x1 0x1cc 0x1 0x1d0 0x1 0x1d4 0x1 0x1d8 0x1 0x1dc 0x1>;
				};

				cam_pmx_func3 {
					linux,phandle = <0x1a>;
					phandle = <0x1a>;
					pinctrl-single,bias-pulldown = <0xa000 0xa000 0x0 0xa000>;
					pinctrl-single,bias-pullup = <0x8000 0xc000 0x8000 0xc000>;
					pinctrl-single,pins = <0x1e4 0x1>;
				};

				cam_pmx_func4 {
					linux,phandle = <0x1b>;
					phandle = <0x1b>;
					pinctrl-single,bias-pulldown = <0xa000 0xa000 0x0 0xa000>;
					pinctrl-single,bias-pullup = <0x8000 0xc000 0x8000 0xc000>;
					pinctrl-single,drive-strength = <0x1000 0x1800>;
					pinctrl-single,input-schmitt = <0x0 0x30>;
					pinctrl-single,input-schmitt-enable = <0x40 0x0 0x40 0x40>;
					pinctrl-single,lpm-output = <0x208 0x388>;
					pinctrl-single,pins = <0x114 0x0 0x118 0x0>;
				};

				cam_pmx_func5 {
					linux,phandle = <0x1c>;
					phandle = <0x1c>;
					pinctrl-single,bias-pulldown = <0xa000 0xa000 0x0 0xa000>;
					pinctrl-single,bias-pullup = <0x8000 0xc000 0x8000 0xc000>;
					pinctrl-single,drive-strength = <0x1000 0x1800>;
					pinctrl-single,input-schmitt = <0x0 0x30>;
					pinctrl-single,input-schmitt-enable = <0x40 0x0 0x40 0x40>;
					pinctrl-single,lpm-output = <0x208 0x388>;
					pinctrl-single,pins = <0x1f0 0x0 0x1f4 0x0>;
				};

				cam_pmx_gpio {
					linux,phandle = <0x18>;
					phandle = <0x18>;
					pinctrl-single,bias-pulldown = <0xa000 0xa000 0x0 0xa000>;
					pinctrl-single,bias-pullup = <0x8000 0xc000 0x8000 0xc000>;
					pinctrl-single,drive-strength = <0x1000 0x1800>;
					pinctrl-single,input-schmitt = <0x0 0x30>;
					pinctrl-single,input-schmitt-enable = <0x40 0x0 0x40 0x40>;
					pinctrl-single,lpm-output = <0x208 0x388>;
					pinctrl-single,pins = <0x1e0 0x0>;
				};

				camera_i2c_pmx {
					linux,phandle = <0x4b>;
					phandle = <0x4b>;
					pinctrl-single,bias-pulldown = <0x0 0xa000 0x0 0xa000>;
					pinctrl-single,bias-pullup = <0x0 0xc000 0x0 0xc000>;
					pinctrl-single,drive-strength = <0x1000 0x1800>;
					pinctrl-single,input-schmitt = <0x0 0x30>;
					pinctrl-single,input-schmitt-enable = <0x40 0x0 0x40 0x40>;
					pinctrl-single,lpm-output = <0x288 0x388>;
					pinctrl-single,pins = <0x154 0x0 0x150 0x0>;
				};

				charger_i2c_pmx {
					linux,phandle = <0x44>;
					phandle = <0x44>;
					pinctrl-single,bias-pulldown = <0x8000 0xa000 0x8000 0xa000>;
					pinctrl-single,bias-pullup = <0xc000 0xc000 0x0 0xc000>;
					pinctrl-single,drive-strength = <0x1000 0x1800>;
					pinctrl-single,input-schmitt = <0x0 0x30>;
					pinctrl-single,input-schmitt-enable = <0x40 0x0 0x40 0x40>;
					pinctrl-single,lpm-output = <0x288 0x388>;
					pinctrl-single,pins = <0x120 0x0 0x11c 0x0>;
				};

				codec_int {
					LPM_PULLHIGH;
					linux,phandle = <0x31>;
					phandle = <0x31>;
					pinctrl-single,bias-pulldown = <0x8000 0xa000 0x8000 0xa000>;
					pinctrl-single,bias-pullup = <0xc000 0xc000 0x0 0xc000>;
					pinctrl-single,drive-strength = <0x1000 0x1800>;
					pinctrl-single,input-schmitt = <0x0 0x30>;
					pinctrl-single,input-schmitt-enable = <0x40 0x0 0x40 0x40>;
					pinctrl-single,lpm-output = <0x0 0x388>;
					pinctrl-single,pins = <0xd0 0x0>;
				};

				dvc_pmx_func {
					linux,phandle = <0x2e>;
					phandle = <0x2e>;
					pinctrl-single,bias-pulldown = <0x0 0xa000 0x0 0xa000>;
					pinctrl-single,bias-pullup = <0x0 0xc000 0x0 0xc000>;
					pinctrl-single,drive-strength = <0x1000 0x1800>;
					pinctrl-single,input-schmitt = <0x0 0x30>;
					pinctrl-single,input-schmitt-enable = <0x40 0x0 0x40 0x40>;
					pinctrl-single,lpm-output = <0x0 0x388>;
					pinctrl-single,pins = <0x188 0x6 0x18c 0x6>;
				};

				gdet_gpio {
					LPM_PULLHIGH;
					linux,phandle = <0x30>;
					phandle = <0x30>;
					pinctrl-single,bias-pulldown = <0x8000 0xa000 0x8000 0xa000>;
					pinctrl-single,bias-pullup = <0xc000 0xc000 0x0 0xc000>;
					pinctrl-single,drive-strength = <0x1000 0x1800>;
					pinctrl-single,input-schmitt = <0x0 0x30>;
					pinctrl-single,input-schmitt-enable = <0x40 0x0 0x40 0x40>;
					pinctrl-single,lpm-output = <0x0 0x388>;
					pinctrl-single,pins = <0x230 0x0>;
				};

				gpio-range {
					#pinctrl-single,gpio-range-cells = <0x3>;
					linux,phandle = <0x32>;
					phandle = <0x32>;
				};

				gpio_charger__func1 {
					linux,phandle = <0x45>;
					phandle = <0x45>;
					pinctrl-single,bias-pulldown = <0x0 0xa000 0x0 0xa000>;
					pinctrl-single,bias-pullup = <0x0 0xc000 0x0 0xc000>;
					pinctrl-single,drive-strength = <0x1000 0x1800>;
					pinctrl-single,input-schmitt = <0x0 0x30>;
					pinctrl-single,input-schmitt-enable = <0x40 0x0 0x40 0x40>;
					pinctrl-single,lpm-output = <0x0 0x388>;
					pinctrl-single,pins = <0xfc 0x0>;
				};

				gpio_charger_func2 {
					linux,phandle = <0x46>;
					phandle = <0x46>;
					pinctrl-single,bias-pulldown = <0xa000 0xa000 0x0 0xa000>;
					pinctrl-single,bias-pullup = <0x8000 0xc000 0x8000 0xc000>;
					pinctrl-single,drive-strength = <0x1000 0x1800>;
					pinctrl-single,input-schmitt = <0x0 0x30>;
					pinctrl-single,input-schmitt-enable = <0x40 0x0 0x40 0x40>;
					pinctrl-single,lpm-output = <0x0 0x388>;
					pinctrl-single,pins = <0x12c 0x0>;
				};

				gpio_keys_func {
					linux,phandle = <0x3e>;
					phandle = <0x3e>;
					pinctrl-single,bias-pulldown = <0x0 0xa000 0x0 0xa000>;
					pinctrl-single,bias-pullup = <0x0 0xc000 0x0 0xc000>;
					pinctrl-single,drive-strength = <0x1000 0x1800>;
					pinctrl-single,input-schmitt = <0x0 0x30>;
					pinctrl-single,input-schmitt-enable = <0x40 0x0 0x40 0x40>;
					pinctrl-single,lpm-output = <0x288 0x388>;
					pinctrl-single,pins = <0xe0 0x0 0xe4 0x0 0x110 0x0>;
				};

				gpio_keys_sleep {
					linux,phandle = <0x3f>;
					phandle = <0x3f>;
					pinctrl-single,bias-pulldown = <0x8000 0xa000 0x8000 0xa000>;
					pinctrl-single,bias-pullup = <0xc000 0xc000 0x0 0xc000>;
					pinctrl-single,drive-strength = <0x1000 0x1800>;
					pinctrl-single,input-schmitt = <0x30 0x30>;
					pinctrl-single,input-schmitt-enable = <0x0 0x0 0x40 0x40>;
					pinctrl-single,lpm-output = <0x0 0x388>;
					pinctrl-single,pins = <0x110 0x0>;
				};

				gps_pmx_eclk {
					linux,phandle = <0x57>;
					phandle = <0x57>;
					pinctrl-single,bias-pulldown = <0x0 0xa000 0x0 0xa000>;
					pinctrl-single,bias-pullup = <0x0 0xc000 0x0 0xc000>;
					pinctrl-single,drive-strength = <0x1000 0x1800>;
					pinctrl-single,input-schmitt = <0x0 0x30>;
					pinctrl-single,input-schmitt-enable = <0x40 0x0 0x40 0x40>;
					pinctrl-single,lpm-output = <0x0 0x388>;
					pinctrl-single,pins = <0x210 0x5>;
				};

				gps_pmx_gpio {
					linux,phandle = <0x5a>;
					phandle = <0x5a>;
					pinctrl-single,bias-pulldown = <0x0 0xa000 0x0 0xa000>;
					pinctrl-single,bias-pullup = <0x0 0xc000 0x0 0xc000>;
					pinctrl-single,drive-strength = <0x1000 0x1800>;
					pinctrl-single,input-schmitt = <0x0 0x30>;
					pinctrl-single,input-schmitt-enable = <0x40 0x0 0x40 0x40>;
					pinctrl-single,lpm-output = <0x0 0x388>;
					pinctrl-single,pins = <0x210 0x0>;
				};

				gps_pmx_poweronoff {
					MFP_LPM_DIRVE_LOW;
					linux,phandle = <0x58>;
					phandle = <0x58>;
					pinctrl-single,bias-pulldown = <0xa000 0xa000 0x0 0xa000>;
					pinctrl-single,bias-pullup = <0x8000 0xc000 0x8000 0xc000>;
					pinctrl-single,drive-strength = <0x1000 0x1800>;
					pinctrl-single,input-schmitt = <0x0 0x30>;
					pinctrl-single,input-schmitt-enable = <0x40 0x0 0x40 0x40>;
					pinctrl-single,lpm-output = <0x0 0x388>;
					pinctrl-single,pins = <0xec 0x0>;
				};

				gps_pmx_reset {
					MFP_LPM_DIRVE_HIGH;
					linux,phandle = <0x59>;
					phandle = <0x59>;
					pinctrl-single,bias-pulldown = <0x8000 0xa000 0x8000 0xa000>;
					pinctrl-single,bias-pullup = <0xc000 0xc000 0x0 0xc000>;
					pinctrl-single,drive-strength = <0x1000 0x1800>;
					pinctrl-single,input-schmitt = <0x0 0x30>;
					pinctrl-single,input-schmitt-enable = <0x40 0x0 0x40 0x40>;
					pinctrl-single,lpm-output = <0x0 0x388>;
					pinctrl-single,pins = <0xf0 0x0>;
				};

				grip_gpio_pmx {
					linux,phandle = <0x4a>;
					phandle = <0x4a>;
					pinctrl-single,bias-pulldown = <0x8000 0xa000 0x8000 0xa000>;
					pinctrl-single,bias-pullup = <0xc000 0xc000 0x0 0xc000>;
					pinctrl-single,drive-strength = <0x1000 0x1800>;
					pinctrl-single,input-schmitt = <0x0 0x30>;
					pinctrl-single,input-schmitt-enable = <0x40 0x0 0x40 0x40>;
					pinctrl-single,pins = <0x164 0x0>;
				};

				gssp_func {
					linux,phandle = <0x39>;
					phandle = <0x39>;
					pinctrl-single,bias-pulldown = <0x0 0xa000 0x0 0xa000>;
					pinctrl-single,bias-pullup = <0x0 0xc000 0x0 0xc000>;
					pinctrl-single,drive-strength = <0x1000 0x1800>;
					pinctrl-single,input-schmitt = <0x0 0x30>;
					pinctrl-single,input-schmitt-enable = <0x40 0x0 0x40 0x40>;
					pinctrl-single,lpm-output = <0x0 0x388>;
					pinctrl-single,pins = <0x140 0x1 0x144 0x1 0x148 0x1 0x14c 0x1>;
				};

				gssp_gpio {
					linux,phandle = <0x38>;
					phandle = <0x38>;
					pinctrl-single,bias-pulldown = <0x8000 0xa000 0x8000 0xa000>;
					pinctrl-single,bias-pullup = <0xc000 0xc000 0x0 0xc000>;
					pinctrl-single,drive-strength = <0x1000 0x1800>;
					pinctrl-single,input-schmitt = <0x0 0x30>;
					pinctrl-single,input-schmitt-enable = <0x40 0x0 0x40 0x40>;
					pinctrl-single,lpm-output = <0x0 0x388>;
					pinctrl-single,pins = <0x140 0x0 0x144 0x0 0x148 0x0 0x14c 0x0>;
				};

				i2s_func {
					linux,phandle = <0x35>;
					phandle = <0x35>;
					pinctrl-single,bias-pulldown = <0x8000 0xa000 0x8000 0xa000>;
					pinctrl-single,bias-pullup = <0xc000 0xc000 0x0 0xc000>;
					pinctrl-single,drive-strength = <0x1000 0x1800>;
					pinctrl-single,input-schmitt = <0x0 0x30>;
					pinctrl-single,input-schmitt-enable = <0x40 0x0 0x40 0x40>;
					pinctrl-single,lpm-output = <0x0 0x388>;
					pinctrl-single,pins = <0x130 0x1 0x134 0x1 0x138 0x1 0x13c 0x1>;
				};

				i2s_gpio {
					linux,phandle = <0x34>;
					phandle = <0x34>;
					pinctrl-single,bias-pulldown = <0x8000 0xa000 0x8000 0xa000>;
					pinctrl-single,bias-pullup = <0xc000 0xc000 0x0 0xc000>;
					pinctrl-single,drive-strength = <0x1000 0x1800>;
					pinctrl-single,input-schmitt = <0x0 0x30>;
					pinctrl-single,input-schmitt-enable = <0x40 0x0 0x40 0x40>;
					pinctrl-single,lpm-output = <0x0 0x388>;
					pinctrl-single,pins = <0x130 0x0 0x134 0x0 0x138 0x0 0x13c 0x0>;
				};

				lcd_esd_pmx {
					linux,phandle = <0x4f>;
					phandle = <0x4f>;
					pinctrl-single,bias-pulldown = <0x0 0xa000 0x0 0xa000>;
					pinctrl-single,bias-pullup = <0x0 0xc000 0x0 0xc000>;
					pinctrl-single,drive-strength = <0x1000 0x1800>;
					pinctrl-single,input-schmitt = <0x0 0x30>;
					pinctrl-single,input-schmitt-enable = <0x40 0x0 0x40 0x40>;
					pinctrl-single,lpm-output = <0x308 0x388>;
					pinctrl-single,pins = <0x128 0x0>;
				};

				lcd_pmx {
					linux,phandle = <0x4d>;
					phandle = <0x4d>;
					pinctrl-single,bias-pulldown = <0x8000 0x8000 0x0 0xa000>;
					pinctrl-single,bias-pullup = <0x8000 0x8000 0x0 0xc000>;
					pinctrl-single,drive-strength = <0x1000 0x1800>;
					pinctrl-single,input-schmitt = <0x0 0x30>;
					pinctrl-single,input-schmitt-enable = <0x40 0x0 0x40 0x40>;
					pinctrl-single,lpm-output = <0x208 0x388>;
					pinctrl-single,pins = <0xf4 0x0 0xf8 0x0>;
				};

				lcd_rst_pmx {
					linux,phandle = <0x4e>;
					phandle = <0x4e>;
					pinctrl-single,bias-pulldown = <0x8000 0xa000 0x8000 0xa000>;
					pinctrl-single,bias-pullup = <0xc000 0xc000 0x0 0xc000>;
					pinctrl-single,drive-strength = <0x1000 0x1800>;
					pinctrl-single,input-schmitt = <0x0 0x30>;
					pinctrl-single,input-schmitt-enable = <0x40 0x0 0x40 0x40>;
					pinctrl-single,lpm-output = <0x0 0x388>;
					pinctrl-single,pins = <0x124 0x0>;
				};

				lcd_rst_pmx_sleep {
					linux,phandle = <0x50>;
					phandle = <0x50>;
					pinctrl-single,bias-pulldown = <0xa000 0xa000 0x0 0xa000>;
					pinctrl-single,bias-pullup = <0x8000 0xc000 0x8000 0xc000>;
					pinctrl-single,drive-strength = <0x1000 0x1800>;
					pinctrl-single,input-schmitt = <0x0 0x30>;
					pinctrl-single,input-schmitt-enable = <0x40 0x0 0x40 0x40>;
					pinctrl-single,lpm-output = <0x208 0x388>;
					pinctrl-single,pins = <0x124 0x0>;
				};

				mfp_pins_group_0 {
					linux,phandle = <0x25>;
					phandle = <0x25>;
					pinctrl-single,bias-pulldown = <0x8000 0xa000 0x8000 0xa000>;
					pinctrl-single,bias-pullup = <0xc000 0xc000 0x0 0xc000>;
					pinctrl-single,lpm-output = <0x288 0x388>;
					pinctrl-single,pins = <0x20 0x1 0x1c 0x1 0x18 0x1 0x14 0x1 0x10 0x1 0xc 0x1 0x54 0x0 0x58 0x0 0x60 0x0 0x68 0x1 0x78 0x0 0x48 0x1 0x4c 0x1 0x50 0x1 0x234 0x0 0xcc 0x1 0x6c 0x0 0xd4 0x1>;
				};

				mfp_pins_group_1 {
					linux,phandle = <0x26>;
					phandle = <0x26>;
					pinctrl-single,bias-pulldown = <0x0 0xa000 0x0 0xa000>;
					pinctrl-single,bias-pullup = <0x0 0xc000 0x0 0xc000>;
					pinctrl-single,lpm-output = <0x288 0x388>;
					pinctrl-single,pins = <0x100 0x0 0x8 0x1 0x4 0x1>;
				};

				muic_gpio_pmx {
					linux,phandle = <0x43>;
					phandle = <0x43>;
					pinctrl-single,bias-pulldown = <0x0 0xa000 0x0 0xa000>;
					pinctrl-single,bias-pullup = <0x0 0xc000 0x0 0xc000>;
					pinctrl-single,drive-strength = <0x1000 0x1800>;
					pinctrl-single,input-schmitt = <0x0 0x30>;
					pinctrl-single,input-schmitt-enable = <0x40 0x0 0x40 0x40>;
					pinctrl-single,lpm-output = <0x288 0x388>;
					pinctrl-single,pins = <0x220 0x0>;
				};

				muic_i2c_pmx {
					linux,phandle = <0x42>;
					phandle = <0x42>;
					pinctrl-single,bias-pulldown = <0x0 0xa000 0x0 0xa000>;
					pinctrl-single,bias-pullup = <0x0 0xc000 0x0 0xc000>;
					pinctrl-single,drive-strength = <0x1000 0x1800>;
					pinctrl-single,input-schmitt = <0x0 0x30>;
					pinctrl-single,input-schmitt-enable = <0x40 0x0 0x40 0x40>;
					pinctrl-single,lpm-output = <0x288 0x388>;
					pinctrl-single,pins = <0x1a4 0x0 0x1a0 0x0>;
				};

				sdh1_pmx_func1 {
					linux,phandle = <0x4>;
					phandle = <0x4>;
					pinctrl-single,bias-pulldown = <0xa000 0xa000 0x0 0xa000>;
					pinctrl-single,bias-pullup = <0x8000 0xc000 0x8000 0xc000>;
					pinctrl-single,drive-strength = <0x1000 0x1800>;
					pinctrl-single,input-schmitt = <0x0 0x30>;
					pinctrl-single,input-schmitt-enable = <0x40 0x0 0x40 0x40>;
					pinctrl-single,lpm-output = <0x288 0x388>;
					pinctrl-single,pins = <0x84 0x0 0x88 0x0 0x8c 0x0 0x90 0x0 0xb0 0x0>;
				};

				sdh1_pmx_func2 {
					linux,phandle = <0x5>;
					phandle = <0x5>;
					pinctrl-single,bias-pulldown = <0x0 0xa000 0x0 0xa000>;
					pinctrl-single,bias-pullup = <0x0 0xc000 0x0 0xc000>;
					pinctrl-single,drive-strength = <0x1000 0x1800>;
					pinctrl-single,input-schmitt = <0x0 0x30>;
					pinctrl-single,input-schmitt-enable = <0x40 0x0 0x40 0x40>;
					pinctrl-single,lpm-output = <0x0 0x388>;
					pinctrl-single,pins = <0x94 0x0 0x98 0x0 0x9c 0x0 0xa0 0x0>;
				};

				sdh1_pmx_func3 {
					linux,phandle = <0x6>;
					phandle = <0x6>;
					pinctrl-single,bias-pulldown = <0x0 0xa000 0x0 0xa000>;
					pinctrl-single,bias-pullup = <0x0 0xc000 0x0 0xc000>;
					pinctrl-single,drive-strength = <0x1000 0x1800>;
					pinctrl-single,input-schmitt = <0x0 0x30>;
					pinctrl-single,input-schmitt-enable = <0x40 0x0 0x40 0x40>;
					pinctrl-single,lpm-output = <0x208 0x388>;
					pinctrl-single,pins = <0xa8 0x0>;
				};

				sdh1_pmx_func4 {
					PULL_HIGH;
					linux,phandle = <0x7>;
					phandle = <0x7>;
					pinctrl-single,drive-strength = <0x1000 0x1800>;
					pinctrl-single,input-schmitt = <0x0 0x30>;
					pinctrl-single,input-schmitt-enable = <0x40 0x0 0x40 0x40>;
					pinctrl-single,lpm-output = <0x0 0x388>;
					pinctrl-single,pins = <0xac 0x0>;
				};

				sdh1_pmx_func5 {
					linux,phandle = <0x8>;
					phandle = <0x8>;
					pinctrl-single,bias-pulldown = <0x8000 0xa000 0x8000 0xa000>;
					pinctrl-single,bias-pullup = <0xc000 0xc000 0x0 0xc000>;
					pinctrl-single,lpm-output = <0x288 0x388>;
					pinctrl-single,pins = <0xa4 0x0>;
				};

				sdh1_pmx_func6 {
					linux,phandle = <0x9>;
					phandle = <0x9>;
					pinctrl-single,bias-pulldown = <0x0 0xa000 0x0 0xa000>;
					pinctrl-single,bias-pullup = <0x0 0xc000 0x0 0xc000>;
					pinctrl-single,drive-strength = <0x1000 0x1800>;
					pinctrl-single,input-schmitt = <0x0 0x30>;
					pinctrl-single,input-schmitt-enable = <0x40 0x0 0x40 0x40>;
					pinctrl-single,lpm-output = <0x288 0x388>;
					pinctrl-single,pins = <0x108 0x0>;
				};

				sdh2_pmx_edge_wakeup {
					PULL_LOW;
					linux,phandle = <0x14>;
					phandle = <0x14>;
					pinctrl-single,drive-strength = <0x1000 0x1800>;
					pinctrl-single,input-schmitt = <0x30 0x30>;
					pinctrl-single,input-schmitt-enable = <0x0 0x0 0x40 0x40>;
					pinctrl-single,lpm-output = <0x0 0x388>;
					pinctrl-single,pins = <0x178 0x1>;
				};

				sdh2_pmx_func1 {
					linux,phandle = <0xd>;
					phandle = <0xd>;
					pinctrl-single,bias-pulldown = <0x0 0xa000 0x0 0xa000>;
					pinctrl-single,bias-pullup = <0x0 0xc000 0x0 0xc000>;
					pinctrl-single,drive-strength = <0x0 0x1800>;
					pinctrl-single,input-schmitt = <0x0 0x30>;
					pinctrl-single,input-schmitt-enable = <0x40 0x0 0x40 0x40>;
					pinctrl-single,lpm-output = <0x0 0x388>;
					pinctrl-single,pins = <0x170 0x1 0x174 0x1 0x178 0x1 0x17c 0x1 0x180 0x1>;
				};

				sdh2_pmx_func1_fast {
					linux,phandle = <0x12>;
					phandle = <0x12>;
					pinctrl-single,bias-pulldown = <0x0 0xa000 0x0 0xa000>;
					pinctrl-single,bias-pullup = <0x0 0xc000 0x0 0xc000>;
					pinctrl-single,drive-strength = <0x0 0x1800>;
					pinctrl-single,input-schmitt = <0x0 0x30>;
					pinctrl-single,input-schmitt-enable = <0x40 0x0 0x40 0x40>;
					pinctrl-single,lpm-output = <0x0 0x388>;
					pinctrl-single,pins = <0x170 0x1 0x174 0x1 0x178 0x1 0x17c 0x1 0x180 0x1>;
				};

				sdh2_pmx_func2 {
					linux,phandle = <0xe>;
					phandle = <0xe>;
					pinctrl-single,bias-pulldown = <0xa000 0xa000 0x0 0xa000>;
					pinctrl-single,bias-pullup = <0x8000 0xc000 0x8000 0xc000>;
					pinctrl-single,drive-strength = <0x1000 0x1800>;
					pinctrl-single,input-schmitt = <0x0 0x30>;
					pinctrl-single,input-schmitt-enable = <0x40 0x0 0x40 0x40>;
					pinctrl-single,lpm-output = <0x0 0x388>;
					pinctrl-single,pins = <0x1fc 0x0>;
				};

				sdh2_pmx_func2_fast {
					linux,phandle = <0x13>;
					phandle = <0x13>;
					pinctrl-single,bias-pulldown = <0x0 0xa000 0x0 0xa000>;
					pinctrl-single,bias-pullup = <0x0 0xc000 0x0 0xc000>;
					pinctrl-single,drive-strength = <0x0 0x1800>;
					pinctrl-single,input-schmitt = <0x0 0x30>;
					pinctrl-single,input-schmitt-enable = <0x40 0x0 0x40 0x40>;
					pinctrl-single,lpm-output = <0x208 0x388>;
					pinctrl-single,pins = <0x184 0x1>;
				};

				sdh2_pmx_func3 {
					linux,phandle = <0xf>;
					phandle = <0xf>;
					pinctrl-single,bias-pulldown = <0x8000 0x8000 0x0 0xa000>;
					pinctrl-single,bias-pullup = <0x8000 0x8000 0x0 0xc000>;
					pinctrl-single,drive-strength = <0x1000 0x1800>;
					pinctrl-single,input-schmitt = <0x0 0x30>;
					pinctrl-single,input-schmitt-enable = <0x40 0x0 0x40 0x40>;
					pinctrl-single,pins = <0x1a8 0x0>;
				};

				sdh2_pmx_func4 {
					linux,phandle = <0x10>;
					phandle = <0x10>;
					pinctrl-single,bias-pulldown = <0x8000 0x8000 0x0 0xa000>;
					pinctrl-single,bias-pullup = <0x8000 0x8000 0x0 0xc000>;
					pinctrl-single,drive-strength = <0x1000 0x1800>;
					pinctrl-single,input-schmitt = <0x0 0x30>;
					pinctrl-single,input-schmitt-enable = <0x40 0x0 0x40 0x40>;
					pinctrl-single,lpm-output = <0x208 0x388>;
					pinctrl-single,pins = <0x1f8 0x0>;
				};

				sdh2_pmx_func5 {
					linux,phandle = <0x11>;
					phandle = <0x11>;
					pinctrl-single,bias-pulldown = <0x0 0xa000 0x0 0xa000>;
					pinctrl-single,bias-pullup = <0x0 0xc000 0x0 0xc000>;
					pinctrl-single,drive-strength = <0x0 0x1800>;
					pinctrl-single,input-schmitt = <0x0 0x30>;
					pinctrl-single,input-schmitt-enable = <0x40 0x0 0x40 0x40>;
					pinctrl-single,lpm-output = <0x208 0x388>;
					pinctrl-single,pins = <0x184 0x1>;
				};

				sdh3_pmx_func1 {
					linux,phandle = <0x2>;
					phandle = <0x2>;
					pinctrl-single,bias-pulldown = <0x8000 0xa000 0x8000 0xa000>;
					pinctrl-single,bias-pullup = <0xc000 0xc000 0x0 0xc000>;
					pinctrl-single,drive-strength = <0x1000 0x1800>;
					pinctrl-single,input-schmitt = <0x0 0x30>;
					pinctrl-single,input-schmitt-enable = <0x40 0x0 0x40 0x40>;
					pinctrl-single,lpm-output = <0x288 0x388>;
					pinctrl-single,pins = <0x24 0x1 0x28 0x1 0x2c 0x1 0x30 0x1 0x34 0x1 0x38 0x1 0x3c 0x1 0x40 0x1 0x5c 0x1 0x6c 0x2>;
				};

				sdh3_pmx_func2 {
					linux,phandle = <0x3>;
					phandle = <0x3>;
					pinctrl-single,bias-pulldown = <0x0 0xa000 0x0 0xa000>;
					pinctrl-single,bias-pullup = <0x0 0xc000 0x0 0xc000>;
					pinctrl-single,drive-strength = <0x1000 0x1800>;
					pinctrl-single,input-schmitt = <0x0 0x30>;
					pinctrl-single,input-schmitt-enable = <0x40 0x0 0x40 0x40>;
					pinctrl-single,lpm-output = <0x208 0x388>;
					pinctrl-single,pins = <0x64 0x1>;
				};

				sensors_i2c_pmx {
					linux,phandle = <0x47>;
					phandle = <0x47>;
					pinctrl-single,bias-pulldown = <0x0 0xa000 0x0 0xa000>;
					pinctrl-single,bias-pullup = <0x0 0xc000 0x0 0xc000>;
					pinctrl-single,drive-strength = <0x1000 0x1800>;
					pinctrl-single,input-schmitt = <0x0 0x30>;
					pinctrl-single,input-schmitt-enable = <0x40 0x0 0x40 0x40>;
					pinctrl-single,lpm-output = <0x288 0x388>;
					pinctrl-single,pins = <0x168 0x0 0x16c 0x0>;
				};

				tsp_gpio_func {
					linux,phandle = <0x2b>;
					phandle = <0x2b>;
					pinctrl-single,bias-pulldown = <0x0 0xa000 0x0 0xa000>;
					pinctrl-single,bias-pullup = <0x0 0xc000 0x0 0xc000>;
					pinctrl-single,drive-strength = <0x1000 0x1800>;
					pinctrl-single,input-schmitt = <0x0 0x30>;
					pinctrl-single,input-schmitt-enable = <0x40 0x0 0x40 0x40>;
					pinctrl-single,lpm-output = <0x0 0x388>;
					pinctrl-single,pins = <0x224 0x0>;
				};

				tsp_vendor_func {
					linux,phandle = <0x2c>;
					phandle = <0x2c>;
					pinctrl-single,bias-pulldown = <0x0 0xa000 0x0 0xa000>;
					pinctrl-single,bias-pullup = <0x0 0xc000 0x0 0xc000>;
					pinctrl-single,drive-strength = <0x1000 0x1800>;
					pinctrl-single,input-schmitt = <0x0 0x30>;
					pinctrl-single,input-schmitt-enable = <0x40 0x0 0x40 0x40>;
					pinctrl-single,lpm-output = <0x0 0x388>;
					pinctrl-single,pins = <0x8 0x1 0x4 0x1>;
				};

				twsi0_pmx_func {
					linux,phandle = <0x27>;
					phandle = <0x27>;
					pinctrl-single,bias-pulldown = <0x0 0xa000 0x0 0xa000>;
					pinctrl-single,bias-pullup = <0x0 0xc000 0x0 0xc000>;
					pinctrl-single,drive-strength = <0x1000 0x1800>;
					pinctrl-single,input-schmitt = <0x0 0x30>;
					pinctrl-single,input-schmitt-enable = <0x40 0x0 0x40 0x40>;
					pinctrl-single,lpm-output = <0x288 0x388>;
					pinctrl-single,pins = <0x1e8 0x1 0x1ec 0x1>;
				};

				twsi0_pmx_gpio {
					linux,phandle = <0x28>;
					phandle = <0x28>;
					pinctrl-single,bias-pulldown = <0x0 0xa000 0x0 0xa000>;
					pinctrl-single,bias-pullup = <0x0 0xc000 0x0 0xc000>;
					pinctrl-single,drive-strength = <0x1000 0x1800>;
					pinctrl-single,input-schmitt = <0x0 0x30>;
					pinctrl-single,input-schmitt-enable = <0x40 0x0 0x40 0x40>;
					pinctrl-single,lpm-output = <0x288 0x388>;
					pinctrl-single,pins = <0x1e8 0x0 0x1ec 0x0>;
				};

				twsi1_pmx_func {
					linux,phandle = <0x29>;
					phandle = <0x29>;
					pinctrl-single,bias-pulldown = <0x0 0xa000 0x0 0xa000>;
					pinctrl-single,bias-pullup = <0x0 0xc000 0x0 0xc000>;
					pinctrl-single,drive-strength = <0x1000 0x1800>;
					pinctrl-single,input-schmitt = <0x0 0x30>;
					pinctrl-single,input-schmitt-enable = <0x40 0x0 0x40 0x40>;
					pinctrl-single,lpm-output = <0x288 0x388>;
					pinctrl-single,pins = <0x208 0x5 0x20c 0x5>;
				};

				twsi1_pmx_gpio {
					linux,phandle = <0x2a>;
					phandle = <0x2a>;
					pinctrl-single,bias-pulldown = <0x0 0xa000 0x0 0xa000>;
					pinctrl-single,bias-pullup = <0x0 0xc000 0x0 0xc000>;
					pinctrl-single,drive-strength = <0x1000 0x1800>;
					pinctrl-single,input-schmitt = <0x0 0x30>;
					pinctrl-single,input-schmitt-enable = <0x40 0x0 0x40 0x40>;
					pinctrl-single,lpm-output = <0x288 0x388>;
					pinctrl-single,pins = <0x208 0x0 0x20c 0x0>;
				};

				uart2_pmx_func1 {
					linux,phandle = <0x20>;
					phandle = <0x20>;
					pinctrl-single,bias-pulldown = <0x8000 0xa000 0x8000 0xa000>;
					pinctrl-single,bias-pullup = <0xc000 0xc000 0x0 0xc000>;
					pinctrl-single,drive-strength = <0x1000 0x1800>;
					pinctrl-single,input-schmitt = <0x0 0x30>;
					pinctrl-single,input-schmitt-enable = <0x40 0x0 0x40 0x40>;
					pinctrl-single,lpm-output = <0x0 0x388>;
					pinctrl-single,pins = <0x198 0x6>;
				};

				uart2_pmx_func1_sleep {
					linux,phandle = <0x22>;
					phandle = <0x22>;
					pinctrl-single,bias-pulldown = <0x8000 0xa000 0x8000 0xa000>;
					pinctrl-single,bias-pullup = <0xc000 0xc000 0x0 0xc000>;
					pinctrl-single,drive-strength = <0x1000 0x1800>;
					pinctrl-single,input-schmitt = <0x0 0x30>;
					pinctrl-single,input-schmitt-enable = <0x40 0x0 0x40 0x40>;
					pinctrl-single,lpm-output = <0x0 0x388>;
					pinctrl-single,pins = <0x198 0x6>;
				};

				uart2_pmx_func2 {
					linux,phandle = <0x21>;
					phandle = <0x21>;
					pinctrl-single,bias-pulldown = <0x8000 0xa000 0x8000 0xa000>;
					pinctrl-single,bias-pullup = <0xc000 0xc000 0x0 0xc000>;
					pinctrl-single,drive-strength = <0x1000 0x1800>;
					pinctrl-single,input-schmitt = <0x0 0x30>;
					pinctrl-single,input-schmitt-enable = <0x40 0x0 0x40 0x40>;
					pinctrl-single,lpm-output = <0x0 0x388>;
					pinctrl-single,pins = <0x19c 0x6>;
				};

				uart3_pmx_func {
					linux,phandle = <0x23>;
					phandle = <0x23>;
					pinctrl-single,bias-pulldown = <0x0 0xa000 0x0 0xa000>;
					pinctrl-single,bias-pullup = <0x0 0xc000 0x0 0xc000>;
					pinctrl-single,drive-strength = <0x1000 0x1800>;
					pinctrl-single,input-schmitt = <0x0 0x30>;
					pinctrl-single,input-schmitt-enable = <0x40 0x0 0x40 0x40>;
					pinctrl-single,lpm-output = <0x0 0x388>;
					pinctrl-single,pins = <0x190 0x1 0x194 0x1>;
				};

				usim_pmx_gpio {
					linux,phandle = <0x3a>;
					phandle = <0x3a>;
					pinctrl-single,bias-pulldown = <0x8000 0xa000 0x8000 0xa000>;
					pinctrl-single,bias-pullup = <0xc000 0xc000 0x0 0xc000>;
					pinctrl-single,drive-strength = <0x1000 0x1800>;
					pinctrl-single,input-schmitt = <0x0 0x30>;
					pinctrl-single,input-schmitt-enable = <0x40 0x0 0x40 0x40>;
					pinctrl-single,lpm-output = <0x288 0x388>;
					pinctrl-single,pins = <0x44 0x1>;
				};

				usim_pmx_sleep {
					linux,phandle = <0x3b>;
					phandle = <0x3b>;
					pinctrl-single,bias-pulldown = <0x8000 0xa000 0x8000 0xa000>;
					pinctrl-single,bias-pullup = <0xc000 0xc000 0x0 0xc000>;
					pinctrl-single,drive-strength = <0x1000 0x1800>;
					pinctrl-single,input-schmitt = <0x30 0x30>;
					pinctrl-single,input-schmitt-enable = <0x0 0x0 0x40 0x40>;
					pinctrl-single,lpm-output = <0x0 0x388>;
					pinctrl-single,pins = <0x44 0x1>;
				};

				vib_gpio_pmx {
					linux,phandle = <0x4c>;
					phandle = <0x4c>;
					pinctrl-single,bias-pulldown = <0xa000 0xa000 0x0 0xa000>;
					pinctrl-single,bias-pullup = <0x8000 0xc000 0x8000 0xc000>;
					pinctrl-single,drive-strength = <0x1000 0x1800>;
					pinctrl-single,input-schmitt = <0x0 0x30>;
					pinctrl-single,input-schmitt-enable = <0x40 0x0 0x40 0x40>;
					pinctrl-single,lpm-output = <0x0 0x388>;
					pinctrl-single,pins = <0x22c 0x0>;
				};
			};

			pmu@d4050000 {
				compatible = "mrvl,mmp-pmu-mpmu";
				reg = <0xd4050000 0x1050>;
			};

			pxa-ssp-dai@1 {
				asram = <0x1f>;
				burst_size = <0x4>;
				capture_buffer_bytes = <0x5000>;
				capture_period_bytes = <0x1000>;
				compatible = "mrvl,pxa-ssp-dai";
				dma-names = "rx", "tx";
				dmas = <0x36 0x1 0x36 0x0>;
				linux,phandle = <0x40>;
				phandle = <0x40>;
				pinctrl-0 = <0x34>;
				pinctrl-1 = <0x35>;
				pinctrl-names = "default", "ssp";
				platform_driver_name = "tdma_platform";
				playback_buffer_bytes = <0x5000>;
				playback_period_bytes = <0x1000>;
				port = <0x33>;
				reg = <0x1 0x0>;
				ssp-gpio = <0xc 0x15 0x0 0xc 0x16 0x0 0xc 0x17 0x0 0xc 0x18 0x0>;
			};

			pxa-ssp-dai@4 {
				burst_size = <0x8>;
				capture_buffer_bytes = <0x20000>;
				capture_period_bytes = <0x1000>;
				compatible = "mrvl,pxa-ssp-dai";
				dma-names = "rx", "tx";
				dmas = <0x1e 0x6 0x0 0x1e 0x7 0x0>;
				linux,phandle = <0x41>;
				phandle = <0x41>;
				pinctrl-0 = <0x38>;
				pinctrl-1 = <0x39>;
				pinctrl-names = "default", "ssp";
				platform_driver_name = "pdma_platform";
				playback_buffer_bytes = <0x20000>;
				playback_period_bytes = <0x1000>;
				port = <0x37>;
				reg = <0x4 0x0>;
				ssp-gpio = <0xc 0x19 0x0 0xc 0x1a 0x0 0xc 0x1b 0x0 0xc 0x1c 0x0>;
			};

			rtc@d4010000 {
				compatible = "mrvl,mmp-rtc";
				interrupt-names = "rtc 1Hz", "rtc alarm";
				interrupts = <0x0 0x5 0x4 0x0 0x6 0x4>;
				reg = <0xd4010000 0x100>;
				status = "okay";
			};

			seh@d4080000 {
				compatible = "mrvl,seh";
				interrupt-names = "WDT";
				interrupts = <0x0 0x23 0x4>;
				reg = <0xd4080000 0x100>;
				status = "okay";
				watchdog-type = <0x0>;
			};

			ssp@d401b000 {
				compatible = "mrvl,pxa910-ssp";
				interrupts = <0x0 0x3 0x4>;
				reg = <0xd401b000 0x90>;
				ssp-id = <0x1>;
			};

			ssp@d4039000 {
				compatible = "mrvl,pxa910-ssp";
				interrupts = <0x0 0x22 0x4>;
				linux,phandle = <0x37>;
				phandle = <0x37>;
				reg = <0xd4039000 0x90>;
				ssp-id = <0x5>;
			};

			ssp@d42a0c00 {
				compatible = "mrvl,pxa910-ssp";
				interrupts = <0x0 0x2 0x4>;
				linux,phandle = <0x33>;
				phandle = <0x33>;
				reg = <0xd42a0c00 0x90>;
				ssp-id = <0x2>;
			};

			thermal@d4013200 {
				compatible = "marvell,pxa1088-thermal";
				interrupts = <0x0 0x3c 0x4>;
				reg = <0xd4013200 0x50>;
				status = "ok";
				trigger_levels_count = <0x0>;
				type = <0x0>;
			};

			timer@d4014000 {
				compatible = "marvell,mmp-timer";
				marvell,timer-apb_freq = <0x18cba80>;
				marvell,timer-fc_freq = <0x319750>;
				marvell,timer-flag = <0x0>;
				marvell,timer-id = <0x0>;
				reg = <0xd4014000 0xc8>;

				counter0 {
					interrupts = <0x0 0xd 0x4>;
					marvell,timer-counter-cnt_freq = <0x8000>;
					marvell,timer-counter-cnt_rating = <0xc8>;
					marvell,timer-counter-cpu = <0x0>;
					marvell,timer-counter-id = <0x0>;
					marvell,timer-counter-mode = <0x1>;
					marvell,timer-counter-usage = <0x4>;
				};

				counter1 {
					interrupts = <0x0 0xe 0x4>;
					marvell,timer-counter-cnt_freq = <0x8000>;
					marvell,timer-counter-cnt_rating = <0xc8>;
					marvell,timer-counter-cpu = <0x1>;
					marvell,timer-counter-id = <0x1>;
					marvell,timer-counter-mode = <0x1>;
					marvell,timer-counter-usage = <0x4>;
				};

				counter2 {
					interrupts = <0x0 0xe 0x4>;
					marvell,timer-counter-cnt_freq = <0x8000>;
					marvell,timer-counter-cnt_rating = <0xc8>;
					marvell,timer-counter-cpu = <0x0>;
					marvell,timer-counter-id = <0x2>;
					marvell,timer-counter-mode = <0x0>;
					marvell,timer-counter-usage = <0x1>;
				};
			};

			timer@d4016000 {
				compatible = "marvell,mmp-timer";
				marvell,timer-apb_freq = <0x18cba80>;
				marvell,timer-fc_freq = <0x319750>;
				marvell,timer-flag = <0x0>;
				marvell,timer-id = <0x1>;
				reg = <0xd4016000 0xc8>;

				counter0 {
					interrupts = <0x0 0x1d 0x4>;
					marvell,timer-counter-cnt_freq = <0x8000>;
					marvell,timer-counter-cnt_rating = <0xc8>;
					marvell,timer-counter-cpu = <0x2>;
					marvell,timer-counter-id = <0x0>;
					marvell,timer-counter-mode = <0x1>;
					marvell,timer-counter-usage = <0x4>;
				};

				counter1 {
					interrupts = <0x0 0x1e 0x4>;
					marvell,timer-counter-cnt_freq = <0x8000>;
					marvell,timer-counter-cnt_rating = <0xc8>;
					marvell,timer-counter-cpu = <0x3>;
					marvell,timer-counter-id = <0x1>;
					marvell,timer-counter-mode = <0x1>;
					marvell,timer-counter-usage = <0x4>;
				};

				counter2 {
					interrupts = <0x0 0x1e 0x4>;
					marvell,timer-counter-cnt_freq = <0x319750>;
					marvell,timer-counter-cnt_rating = <0xc8>;
					marvell,timer-counter-cpu = <0x0>;
					marvell,timer-counter-id = <0x2>;
					marvell,timer-counter-mode = <0x0>;
					marvell,timer-counter-usage = <0x8>;
				};
			};

			uart@d4017000 {
				compatible = "mrvl,mmp-uart";
				dma-names = "rx", "tx";
				dmas = <0x1e 0x15 0x1 0x1e 0x16 0x1>;
				edge-wakeup-gpio = <0x2f>;
				interrupts = <0x0 0x1b 0x4>;
				lpm-qos = <0x2>;
				pinctrl-0 = <0x20 0x21>;
				pinctrl-1 = <0x22 0x21>;
				pinctrl-names = "default", "sleep";
				reg = <0xd4017000 0x1000>;
				status = "okay";
			};

			uart@d4018000 {
				compatible = "mrvl,mmp-uart";
				dma-names = "rx", "tx";
				dmas = <0x1e 0x17 0x1 0x1e 0x18 0x1>;
				interrupts = <0x0 0x1c 0x4>;
				lpm-qos = <0x2>;
				pinctrl-0 = <0x23>;
				pinctrl-names = "default";
				reg = <0xd4018000 0x1000>;
				status = "okay";
			};

			uart@d4036000 {
				compatible = "mrvl,mmp-uart";
				dma-names = "rx", "tx";
				dmas = <0x1e 0x4 0x1 0x1e 0x5 0x1>;
				interrupts = <0x0 0x3b 0x4>;
				lpm-qos = <0x2>;
				reg = <0xd4036000 0x1000>;
				status = "disabled";
			};

			usim {
				compatible = "usim_event";
				edge-wakeup-gpio = <0x65>;
				pinctrl-0 = <0x3a>;
				pinctrl-1 = <0x3b>;
				pinctrl-names = "default", "sleep";
				status = "okay";
			};

			watchdog@d4080000 {
				compatible = "marvell,pxa-wdt";
				reg = <0xd4080000 0xff 0xd4050000 0x1024>;
				status = "okay";
			};
		};

		axi@d4200000 {
			#address-cells = <0x1>;
			#size-cells = <0x1>;
			compatible = "mrvl,axi-bus", "simple-bus";
			ranges;
			reg = <0xd4200000 0x200000>;

			area51_ipc@0xD4240000 {
				compatible = "marvell, uio-area51";
				reg = <0xd4240000 0x3ffff>;
				status = "disabled";
			};

			area51_isp@0xD420F000 {
				compatible = "marvell, AREA51-ISP";
				interrupts = <0x0 0xf 0x4>;
				reg = <0xd420f000 0xffff>;
				reg-name = "area51-regs";
				status = "disabled";
			};

			ccic@d420a000 {
				cam_avdd-supply = <0x15>;
				cam_core-supply = <0x17>;
				cam_io-supply = <0x16>;
				cam_rst = <0xc 0xf 0x0>;
				cam_stby = <0xc 0xe 0x0>;
				compatible = "marvell,mmp-ccic";
				dma-burst = <0x40>;
				interrupts = <0x0 0x2a 0x4>;
				lpm-qos = <0x2>;
				mclk-div = <0xd>;
				mclk-gpio = <0xc 0x4d 0x0>;
				mclk-src = <0x3>;
				pinctrl-0 = <0x18 0x19 0x1a 0x1b 0x1c>;
				pinctrl-1 = <0x1d 0x19 0x1a 0x1b 0x1c>;
				pinctrl-names = "default", "enable";
				reg = <0xd420a000 0x2ff 0xd4282800 0x1ff>;
				reg-names = "ccic-regs", "apmu-regs";
				status = "okay";
				vt_cam_rst = <0xc 0x51 0x0>;
				vt_cam_stby = <0xc 0x52 0x0>;
			};

			coda7542@d420d000 {
				compatible = "mrvl,mmp-coda7542";
				interrupts = <0x0 0x19 0x4>;
				marvell,nv21_support = <0x0>;
				marvell,sram-internal = <0x1>;
				reg = <0xd420d000 0x1000 0xd1004000 0x11600>;
				status = "okay";
			};

			disp@d420b000 {
				compatible = "marvell,mmp-disp";
				interrupts = <0x0 0x29 0x4>;
				lpm-qos = <0x3>;
				lpm-qos-d1p = <0x2>;
				marvell,disp-name = "disp_name";
				marvell,path-num = <0x1>;
				reg = <0xd420b000 0x1fc>;
				status = "okay";

				path1 {
					marvell,link-config = <0x1>;
					marvell,output-type = <0x1>;
					marvell,overlay-num = <0x1>;
					marvell,overlay-table = <0x1>;
					marvell,path-config = <0x10>;
					marvell,path-name = "mmp_pnpath";

					WVGA {
						disp1_clksrc = "pll1_416m";
						dsipll_clksrc = "pll3";
						pn_sclk_clksrc = "disp1";
					};
				};
			};

			dsi@d420b800 {
				compatible = "marvell,mmp-dsi";
				interrupts = <0x0 0x35 0x4>;
				marvell,burst-mode = <0x2>;
				marvell,dsi-lanes = <0x4>;
				marvell,hbp-en;
				marvell,hfp-en;
				marvell,phy-name = "mmp_dsi1";
				marvell,plat-path-name = "mmp_pnpath";
				reg = <0xd420b800 0x1ec>;
				status = "okay";
			};

			ehci@d4208100 {
				compatible = "marvell,pxa-u2oehci";
				interrupts = <0x0 0x2c 0x4>;
				reg = <0xd4208100 0x200>;
				status = "disabled";
			};

			fbbase {
				compatible = "marvell,mmp-fb";
				marvell,buffer-num = <0x3>;
				marvell,default-pixfmt = <0x108>;
				marvell,fb-mem = <0x17000000>;
				marvell,fb-name = "mmp-fb";
				marvell,overlay-id = <0x1>;
				marvell,path-name = "mmp_pnpath";
				status = "okay";
			};

			fboverlay@0 {
				compatible = "marvell,mmp-fb-overlay";
				reg = <0x0 0x0>;
				status = "disabled";
			};

			fboverlay@1 {
				compatible = "marvell,mmp-fb-overlay";
				reg = <0x1 0x0>;
				status = "disabled";
			};

			fboverlay@2 {
				compatible = "marvell,mmp-fb-overlay";
				reg = <0x2 0x0>;
				status = "disabled";
			};

			geu {
				compatible = "marvell,mmp-geu";
				dma-names = "rx", "tx";
				dmas = <0x1e 0x44 0x1 0x1e 0x45 0x1>;
				interrupts = <0x0 0x28 0x4>;
				lpm-qos = <0x2>;
				reg = <0xd4201000 0x1000>;
				status = "okay";
			};

			mc_ccic@d420a000 {
				compatible = "marvell, AREA51-CCIC";
				fclk-mhz = <0x1a0>;
				interrupts = <0x0 0x2a 0x4>;
				mclk-mhz = <0x18>;
				status = "disabled";
			};

			otg@d4208100 {
				compatible = "marvell,mv-otg";
				interrupts = <0x0 0x2c 0x4>;
				lpm-qos = <0x2>;
				marvell,ehci-name = "pxa-u2oehci";
				marvell,udc-name = "mv-udc";
				reg = <0xd4208100 0x200>;
				status = "disabled";
			};

			pmu@d4282800 {
				compatible = "mrvl,mmp-pmu-apmu";
				reg = <0xd4282800 0x1b0>;
			};

			sdh@d4280000 {
				bus-width = <0x4>;
				cd-gpios = <0xc 0xb 0x0>;
				cd-inverted;
				compatible = "mrvl,pxav3-mmc";
				interrupts = <0x0 0x27 0x4>;
				lpm-qos = <0x2>;
				marvell,sdh-dtr-data = <0x0 0x18cba80 0x632ea00 0x0 0x0 0x3 0x3197500 0x632ea00 0x0 0x0 0x7 0x3197500 0x632ea00 0x0 0x0 0x9 0xffffffff 0x632ea00 0x0 0x0>;
				marvell,sdh-flags = <0x81>;
				marvell,sdh-host-caps-disable = <0x7a0000>;
				marvell,sdh-host-caps2 = <0x100>;
				marvell,sdh-pm-runtime-en;
				marvell,sdh-quirks = <0x18000>;
				marvell,sdh-quirks2 = <0x40>;
				pinctrl-0 = <0x4 0x5 0x6 0x7 0x8 0x9>;
				pinctrl-names = "default";
				reg = <0xd4280000 0x120>;
				status = "okay";
				vmmc-supply = <0xb>;
				vqmmc-supply = <0xa>;
				wp-inverted;
			};

			sdh@d4280800 {
				bus-width = <0x4>;
				compatible = "mrvl,pxav3-mmc";
				interrupts = <0x0 0x27 0x4>;
				linux,phandle = <0x3c>;
				lpm-qos = <0x2>;
				marvell,sdh-dtr-data = <0x0 0x18cba80 0x632ea00 0x0 0x0 0x3 0x2aea540 0x5503649 0x0 0x0 0x6 0xc65d400 0xc65d400 0x0 0x0 0x9 0xffffffff 0x5503649 0x0 0x0>;
				marvell,sdh-flags = <0xb9>;
				marvell,sdh-host-caps2 = <0x40000>;
				marvell,sdh-pm-caps = <0x1>;
				marvell,sdh-quirks = <0x8000>;
				marvell,sdh-quirks2 = <0x1c0>;
				mrvl,clk-delay-cycles = <0x0>;
				phandle = <0x3c>;
				pinctrl-0 = <0xd 0xe 0xf 0x10 0x11>;
				pinctrl-1 = <0x12 0x13 0xf 0x10 0x11>;
				pinctrl-2 = <0x14>;
				pinctrl-names = "default", "fast", "sleep";
				reg = <0xd4280800 0x120>;
				status = "okay";
			};

			sdh@d4281000 {
				bus-width = <0x8>;
				compatible = "mrvl,pxav3-mmc";
				interrupts = <0x0 0x27 0x4>;
				lpm-qos = <0x2>;
				marvell,sdh-dtr-data = <0x0 0x18cba80 0x632ea00 0x0 0x0 0x2 0x3197500 0x632ea00 0x0 0x0 0x7 0x3197500 0x632ea00 0xd4 0x0 0x9 0xffffffff 0x632ea00 0x0 0x0>;
				marvell,sdh-flags = <0x85>;
				marvell,sdh-host-caps = <0x800>;
				marvell,sdh-host-caps2 = <0x8002>;
				marvell,sdh-pm-runtime-en;
				marvell,sdh-quirks = <0x8000>;
				marvell,sdh-quirks2 = <0x40>;
				non-removable;
				pinctrl-0 = <0x2 0x3>;
				pinctrl-names = "default";
				reg = <0xd4281000 0x120>;
				status = "okay";
			};

			squ@d42a0800 {
				#dma-cells = <0x1>;
				asram = <0x1f>;
				compatible = "marvell,pxa910-squ";
				interrupts = <0x0 0x2e 0x4>;
				linux,phandle = <0x36>;
				phandle = <0x36>;
				reg = <0xd42a0800 0x100>;
			};

			udc@d4208100 {
				compatible = "marvell,mv-udc";
				interrupts = <0x0 0x2c 0x4>;
				lpm-qos = <0x2>;
				reg = <0xd4208100 0x200>;
				status = "okay";
			};

			usbphy@d4207000 {
				compatible = "marvell,usb2-phy-40lp";
				marvell,ehci-name = "pxa-u2oehci";
				marvell,otg-name = "mv-otg";
				marvell,udc-name = "mv-udc";
				reg = <0xd4207000 0x200>;
				status = "okay";
			};

			vpu-devfreq {
				compatible = "marvell,devfreq-vpu";
				status = "okay";
			};

			wakeupgen@d4282000 {
				compatible = "mrvl,mmp-intc-wakeupgen";
				mrvl,intc-for-cp = <0x0 0x1f 0x20>;
				mrvl,intc-gbl-mask = <0x228 0x3 0x238 0x3 0x248 0x3 0x258 0x3>;
				mrvl,intc-nr-irqs = <0x4c>;
				mrvl,intc-wake-clr = <0x9 0x8 0x27 0x43>;
				reg = <0xd4282000 0x1000 0xd4282800 0x12c>;
			};
		};

		ddr@c0100000 {
			compatible = "marvell,devfreq-ddr";
			marvell,qos;
			reg = <0xc0100000 0x488>;
			status = "okay";
		};

		ramoops {
			compatible = "pstore,ramoops";
			console-size = <0x30000>;
			dump-oops = <0x0>;
			mem-address = <0x8100000>;
			mem-size = <0x40000>;
			record-size = <0x8000>;
			status = "okay";
		};

		soc-camera@0 {
			compatible = "soc-camera-pdrv";
			reg = <0x0 0x0>;
			status = "okay";
		};

		soc-camera@1 {
			compatible = "soc-camera-pdrv";
			reg = <0x1 0x0>;
			status = "okay";
		};

		soc-isp {
			compatible = "soc-isp";
			interrupts = <0x0 0xb 0x4>;
			lpm-qos = <0x2>;
			status = "disabled";
		};

		sram@0xd1004000 {
			compatible = "mmio-sram";
			linux,phandle = <0x1f>;
			phandle = <0x1f>;
			reg = <0xd1004000 0xaa00>;
		};
	};

	sound {
		compatible = "marvell,pxa-88pm805-snd-card";
		ssp-controllers = <0x40 0x41>;
	};

	timer {
		clock-frequency = <0x0>;
		compatible = "arm,armv7-timer";
		interrupts = <0x1 0xd 0x308 0x1 0xe 0x308 0x1 0xb 0x308 0x1 0xa 0x308>;
	};

	tzdd {
		compatible = "pxa-tzdd";
		lpm-qos = <0x2>;
		status = "disabled";
	};

	vibrator {
		android_vibrator,vib_ldo_en = <0xc 0x60 0x0>;
		compatible = "marvell,android-vibrator";
		pinctrl-0 = <0x4c>;
		pinctrl-names = "default";
	};
};
